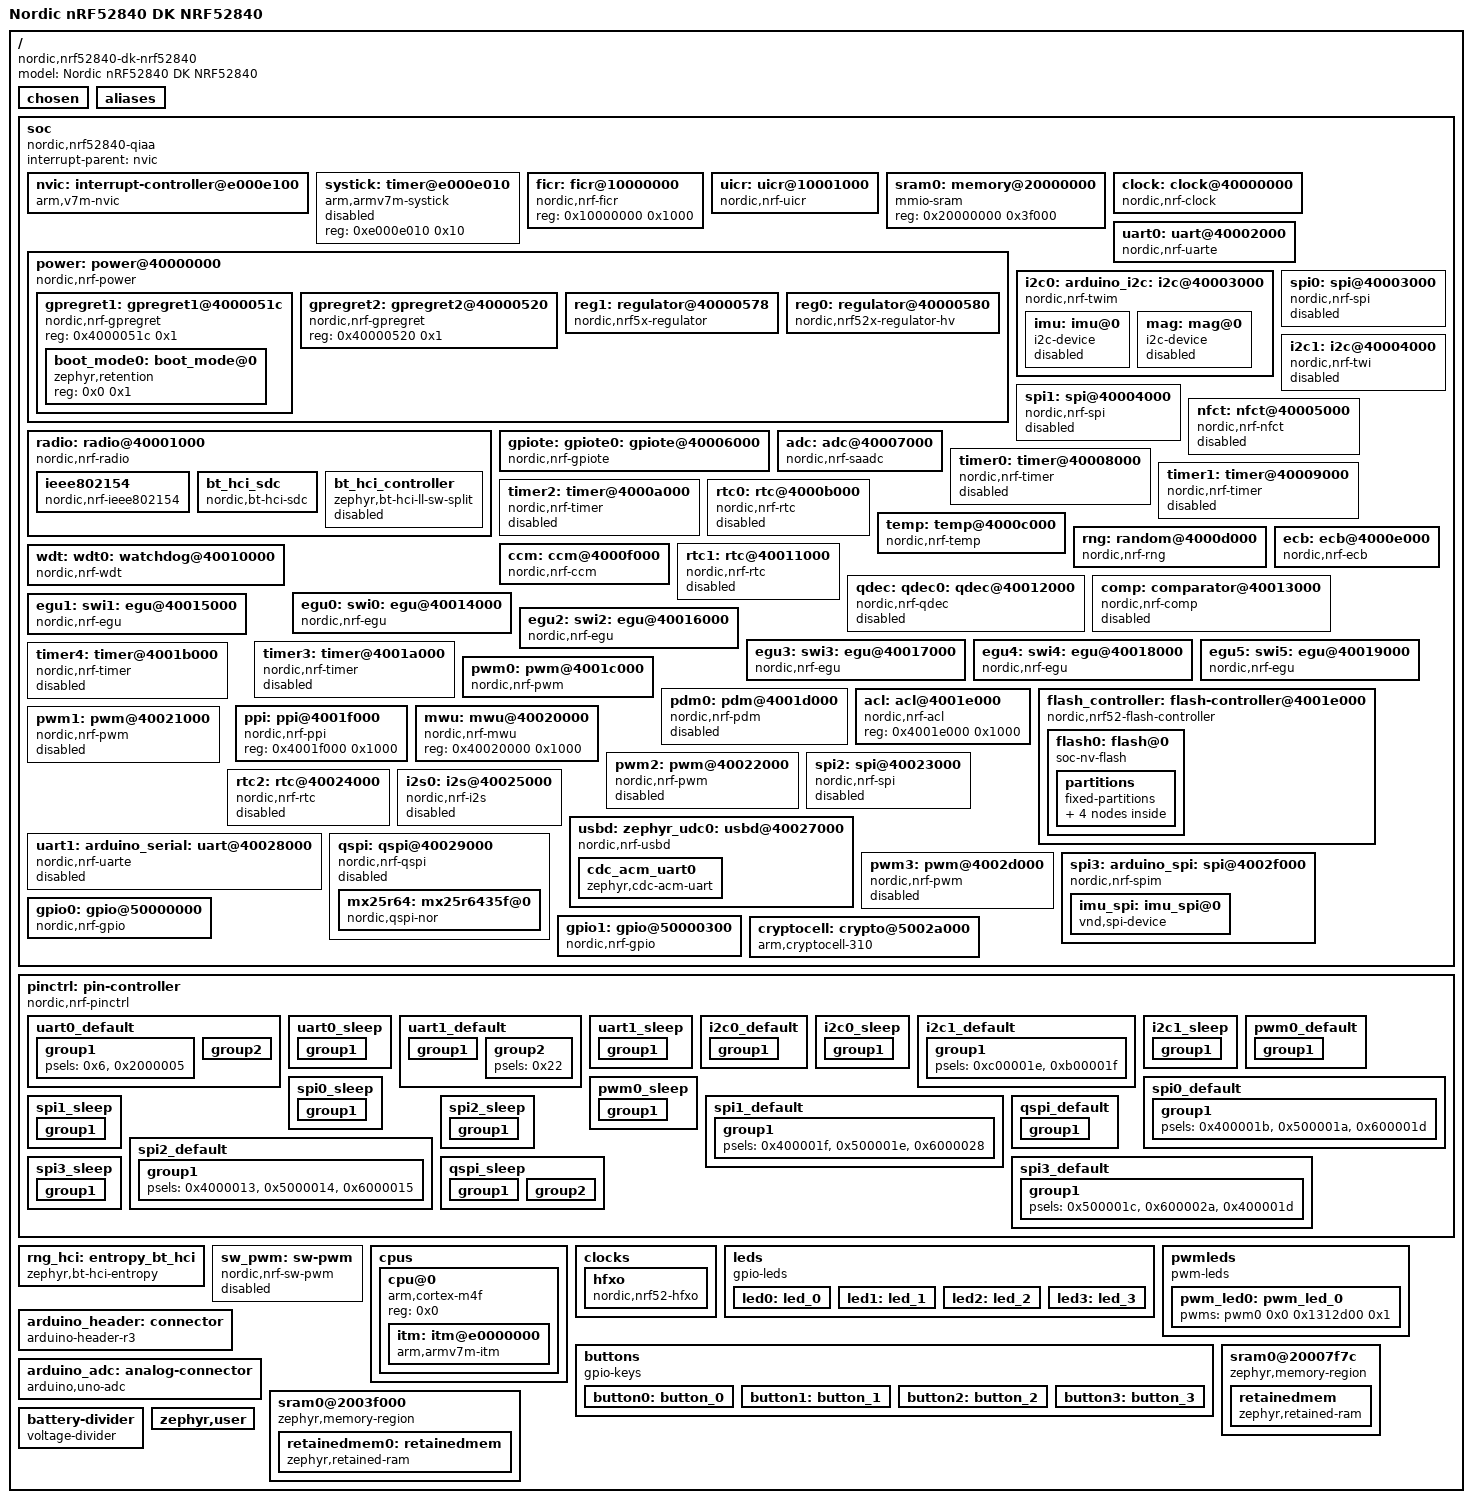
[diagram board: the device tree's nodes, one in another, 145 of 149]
/dts-v1/;

/* node '/' defined in zephyr/dts/common/skeleton.dtsi:9 */
/ {
	#address-cells = < 0x1 >;                   /* in zephyr/dts/common/skeleton.dtsi:10 */
	#size-cells = < 0x1 >;                      /* in zephyr/dts/common/skeleton.dtsi:11 */
	model = "Nordic nRF52840 DK NRF52840";      /* in zephyr/boards/nordic/nrf52840dk/nrf52840dk_nrf52840.dts:14 */
	compatible = "nordic,nrf52840-dk-nrf52840"; /* in zephyr/boards/nordic/nrf52840dk/nrf52840dk_nrf52840.dts:15 */

	/* node '/chosen' defined in zephyr/dts/common/skeleton.dtsi:12 */
	chosen {
		zephyr,bt-hci = &bt_hci_sdc;                 /* in zephyr/dts/arm/nordic/nrf52840.dtsi:10 */
		zephyr,entropy = &cryptocell;                /* in zephyr/dts/arm/nordic/nrf52840.dtsi:11 */
		zephyr,flash-controller = &flash_controller; /* in zephyr/dts/arm/nordic/nrf52840.dtsi:12 */
		zephyr,sram = &sram0;                        /* in zephyr/dts/vendor/nordic/nrf52840_partition.dtsi:9 */
		zephyr,flash = &flash0;                      /* in zephyr/dts/vendor/nordic/nrf52840_partition.dtsi:10 */
		zephyr,code-partition = &slot0_partition;    /* in zephyr/dts/vendor/nordic/nrf52840_partition.dtsi:11 */
		zephyr,console = &cdc_acm_uart0;             /* in app/boards/nrf52840dk_nrf52840.overlay:76 */
		zephyr,shell-uart = &cdc_acm_uart0;          /* in app/boards/nrf52840dk_nrf52840.overlay:77 */
		zephyr,uart-mcumgr = &uart0;                 /* in zephyr/boards/nordic/nrf52840dk/nrf52840dk_nrf52840.dts:20 */
		zephyr,bt-mon-uart = &uart0;                 /* in zephyr/boards/nordic/nrf52840dk/nrf52840dk_nrf52840.dts:21 */
		zephyr,bt-c2h-uart = &uart0;                 /* in zephyr/boards/nordic/nrf52840dk/nrf52840dk_nrf52840.dts:22 */
		zephyr,ieee802154 = &ieee802154;             /* in zephyr/boards/nordic/nrf52840dk/nrf52840dk_nrf52840.dts:23 */
		zephyr,boot-mode = &boot_mode0;              /* in zephyr/boards/nordic/nrf52840dk/nrf52840dk_nrf52840.dts:24 */
	};

	/* node '/aliases' defined in zephyr/dts/common/skeleton.dtsi:13 */
	aliases {
		led0 = &led0;                      /* in zephyr/boards/nordic/nrf52840dk/nrf52840dk_nrf52840.dts:129 */
		led1 = &led1;                      /* in zephyr/boards/nordic/nrf52840dk/nrf52840dk_nrf52840.dts:130 */
		led2 = &led2;                      /* in zephyr/boards/nordic/nrf52840dk/nrf52840dk_nrf52840.dts:131 */
		led3 = &led3;                      /* in zephyr/boards/nordic/nrf52840dk/nrf52840dk_nrf52840.dts:132 */
		pwm-led0 = &pwm_led0;              /* in zephyr/boards/nordic/nrf52840dk/nrf52840dk_nrf52840.dts:133 */
		sw0 = &button0;                    /* in zephyr/boards/nordic/nrf52840dk/nrf52840dk_nrf52840.dts:134 */
		sw1 = &button1;                    /* in zephyr/boards/nordic/nrf52840dk/nrf52840dk_nrf52840.dts:135 */
		sw2 = &button2;                    /* in zephyr/boards/nordic/nrf52840dk/nrf52840dk_nrf52840.dts:136 */
		sw3 = &button3;                    /* in zephyr/boards/nordic/nrf52840dk/nrf52840dk_nrf52840.dts:137 */
		bootloader-led0 = &led0;           /* in zephyr/boards/nordic/nrf52840dk/nrf52840dk_nrf52840.dts:138 */
		mcuboot-button0 = &button0;        /* in zephyr/boards/nordic/nrf52840dk/nrf52840dk_nrf52840.dts:139 */
		mcuboot-led0 = &led0;              /* in zephyr/boards/nordic/nrf52840dk/nrf52840dk_nrf52840.dts:140 */
		watchdog0 = &wdt0;                 /* in zephyr/boards/nordic/nrf52840dk/nrf52840dk_nrf52840.dts:141 */
		retainedmemdevice = &retainedmem0; /* in app/socs/nrf52840.overlay:27 */
	};

	/* node '/soc' defined in zephyr/dts/arm/armv7-m.dtsi:6 */
	soc {
		#address-cells = < 0x1 >;            /* in zephyr/dts/arm/armv7-m.dtsi:7 */
		#size-cells = < 0x1 >;               /* in zephyr/dts/arm/armv7-m.dtsi:8 */
		compatible = "nordic,nrf52840-qiaa",
		             "nordic,nrf52840",
		             "nordic,nrf52",
		             "simple-bus";           /* in zephyr/dts/arm/nordic/nrf52840_qiaa.dtsi:29 */
		interrupt-parent = < &nvic >;        /* in zephyr/dts/arm/armv7-m.dtsi:10 */
		ranges;                              /* in zephyr/dts/arm/armv7-m.dtsi:11 */

		/* node '/soc/interrupt-controller@e000e100' defined in zephyr/dts/arm/armv7-m.dtsi:13 */
		nvic: interrupt-controller@e000e100 {
			#address-cells = < 0x1 >;            /* in zephyr/dts/arm/armv7-m.dtsi:14 */
			compatible = "arm,v7m-nvic";         /* in zephyr/dts/arm/armv7-m.dtsi:15 */
			reg = < 0xe000e100 0xc00 >;          /* in zephyr/dts/arm/armv7-m.dtsi:16 */
			interrupt-controller;                /* in zephyr/dts/arm/armv7-m.dtsi:17 */
			#interrupt-cells = < 0x2 >;          /* in zephyr/dts/arm/armv7-m.dtsi:18 */
			arm,num-irq-priority-bits = < 0x3 >; /* in zephyr/dts/arm/nordic/nrf52840.dtsi:582 */
			phandle = < 0x1 >;                   /* in zephyr/dts/arm/armv7-m.dtsi:10 */
		};

		/* node '/soc/timer@e000e010' defined in zephyr/dts/arm/armv7-m.dtsi:21 */
		systick: timer@e000e010 {
			compatible = "arm,armv7m-systick"; /* in zephyr/dts/arm/armv7-m.dtsi:22 */
			reg = < 0xe000e010 0x10 >;         /* in zephyr/dts/arm/armv7-m.dtsi:23 */
			status = "disabled";               /* in zephyr/dts/arm/nordic/nrf52840.dtsi:587 */
		};

		/* node '/soc/ficr@10000000' defined in zephyr/dts/arm/nordic/nrf52840.dtsi:44 */
		ficr: ficr@10000000 {
			compatible = "nordic,nrf-ficr"; /* in zephyr/dts/arm/nordic/nrf52840.dtsi:45 */
			reg = < 0x10000000 0x1000 >;    /* in zephyr/dts/arm/nordic/nrf52840.dtsi:46 */
			#nordic,ficr-cells = < 0x1 >;   /* in zephyr/dts/arm/nordic/nrf52840.dtsi:47 */
			status = "okay";                /* in zephyr/dts/arm/nordic/nrf52840.dtsi:48 */
		};

		/* node '/soc/uicr@10001000' defined in zephyr/dts/arm/nordic/nrf52840.dtsi:51 */
		uicr: uicr@10001000 {
			compatible = "nordic,nrf-uicr"; /* in zephyr/dts/arm/nordic/nrf52840.dtsi:52 */
			reg = < 0x10001000 0x1000 >;    /* in zephyr/dts/arm/nordic/nrf52840.dtsi:53 */
			status = "okay";                /* in zephyr/dts/arm/nordic/nrf52840.dtsi:54 */
			gpio-as-nreset;                 /* in zephyr/boards/nordic/nrf52840dk/nrf52840dk_nrf52840.dts:158 */
		};

		/* node '/soc/memory@20000000' defined in zephyr/dts/arm/nordic/nrf52840.dtsi:57 */
		sram0: memory@20000000 {
			compatible = "mmio-sram";     /* in zephyr/dts/arm/nordic/nrf52840.dtsi:58 */
			reg = < 0x20000000 0x3f000 >; /* in app/socs/nrf52840.overlay:33 */
		};

		/* node '/soc/clock@40000000' defined in zephyr/dts/arm/nordic/nrf52840.dtsi:61 */
		clock: clock@40000000 {
			compatible = "nordic,nrf-clock"; /* in zephyr/dts/arm/nordic/nrf52840.dtsi:62 */
			reg = < 0x40000000 0x1000 >;     /* in zephyr/dts/arm/nordic/nrf52840.dtsi:63 */
			interrupts = < 0x0 0x1 >;        /* in zephyr/dts/arm/nordic/nrf52840.dtsi:64 */
			status = "okay";                 /* in zephyr/dts/arm/nordic/nrf52840.dtsi:65 */
		};

		/* node '/soc/power@40000000' defined in zephyr/dts/arm/nordic/nrf52840.dtsi:68 */
		power: power@40000000 {
			compatible = "nordic,nrf-power"; /* in zephyr/dts/arm/nordic/nrf52840.dtsi:69 */
			reg = < 0x40000000 0x1000 >;     /* in zephyr/dts/arm/nordic/nrf52840.dtsi:70 */
			interrupts = < 0x0 0x1 >;        /* in zephyr/dts/arm/nordic/nrf52840.dtsi:71 */
			status = "okay";                 /* in zephyr/dts/arm/nordic/nrf52840.dtsi:72 */
			#address-cells = < 0x1 >;        /* in zephyr/dts/arm/nordic/nrf52840.dtsi:73 */
			#size-cells = < 0x1 >;           /* in zephyr/dts/arm/nordic/nrf52840.dtsi:74 */

			/* node '/soc/power@40000000/gpregret1@4000051c' defined in zephyr/dts/arm/nordic/nrf52840.dtsi:76 */
			gpregret1: gpregret1@4000051c {
				#address-cells = < 0x1 >;           /* in zephyr/dts/arm/nordic/nrf52840.dtsi:77 */
				#size-cells = < 0x1 >;              /* in zephyr/dts/arm/nordic/nrf52840.dtsi:78 */
				compatible = "nordic,nrf-gpregret"; /* in zephyr/dts/arm/nordic/nrf52840.dtsi:79 */
				reg = < 0x4000051c 0x1 >;           /* in zephyr/dts/arm/nordic/nrf52840.dtsi:80 */
				status = "okay";                    /* in zephyr/boards/nordic/nrf52840dk/nrf52840dk_nrf52840.dts:296 */

				/* node '/soc/power@40000000/gpregret1@4000051c/boot_mode@0' defined in zephyr/boards/nordic/nrf52840dk/nrf52840dk_nrf52840.dts:298 */
				boot_mode0: boot_mode@0 {
					compatible = "zephyr,retention"; /* in zephyr/boards/nordic/nrf52840dk/nrf52840dk_nrf52840.dts:299 */
					status = "okay";                 /* in zephyr/boards/nordic/nrf52840dk/nrf52840dk_nrf52840.dts:300 */
					reg = < 0x0 0x1 >;               /* in zephyr/boards/nordic/nrf52840dk/nrf52840dk_nrf52840.dts:301 */
				};
			};

			/* node '/soc/power@40000000/gpregret2@40000520' defined in zephyr/dts/arm/nordic/nrf52840.dtsi:84 */
			gpregret2: gpregret2@40000520 {
				#address-cells = < 0x1 >;           /* in zephyr/dts/arm/nordic/nrf52840.dtsi:85 */
				#size-cells = < 0x1 >;              /* in zephyr/dts/arm/nordic/nrf52840.dtsi:86 */
				compatible = "nordic,nrf-gpregret"; /* in zephyr/dts/arm/nordic/nrf52840.dtsi:87 */
				reg = < 0x40000520 0x1 >;           /* in zephyr/dts/arm/nordic/nrf52840.dtsi:88 */
				status = "okay";                    /* in zephyr/dts/arm/nordic/nrf52840.dtsi:89 */
			};

			/* node '/soc/power@40000000/regulator@40000578' defined in zephyr/dts/arm/nordic/nrf52840.dtsi:92 */
			reg1: regulator@40000578 {
				compatible = "nordic,nrf5x-regulator"; /* in zephyr/dts/arm/nordic/nrf52840.dtsi:93 */
				reg = < 0x40000578 0x1 >;              /* in zephyr/dts/arm/nordic/nrf52840.dtsi:94 */
				regulator-name = "REG1";               /* in zephyr/dts/arm/nordic/nrf52840.dtsi:95 */
				regulator-initial-mode = < 0x1 >;      /* in zephyr/boards/nordic/nrf52840dk/nrf52840dk_nrf52840.dts:150 */
			};

			/* node '/soc/power@40000000/regulator@40000580' defined in zephyr/dts/arm/nordic/nrf52840_qiaa.dtsi:19 */
			reg0: regulator@40000580 {
				compatible = "nordic,nrf52x-regulator-hv"; /* in zephyr/dts/arm/nordic/nrf52840_qiaa.dtsi:20 */
				reg = < 0x40000580 0x1 >;                  /* in zephyr/dts/arm/nordic/nrf52840_qiaa.dtsi:21 */
				regulator-name = "REG0";                   /* in zephyr/dts/arm/nordic/nrf52840_qiaa.dtsi:22 */
				status = "okay";                           /* in zephyr/boards/nordic/nrf52840dk/nrf52840dk_nrf52840.dts:146 */
			};
		};

		/* node '/soc/radio@40001000' defined in zephyr/dts/arm/nordic/nrf52840.dtsi:100 */
		radio: radio@40001000 {
			compatible = "nordic,nrf-radio"; /* in zephyr/dts/arm/nordic/nrf52840.dtsi:101 */
			reg = < 0x40001000 0x1000 >;     /* in zephyr/dts/arm/nordic/nrf52840.dtsi:102 */
			interrupts = < 0x1 0x1 >;        /* in zephyr/dts/arm/nordic/nrf52840.dtsi:103 */
			status = "okay";                 /* in zephyr/dts/arm/nordic/nrf52840.dtsi:104 */
			ieee802154-supported;            /* in zephyr/dts/arm/nordic/nrf52840.dtsi:105 */
			ble-2mbps-supported;             /* in zephyr/dts/arm/nordic/nrf52840.dtsi:106 */
			ble-coded-phy-supported;         /* in zephyr/dts/arm/nordic/nrf52840.dtsi:107 */
			tx-high-power-supported;         /* in zephyr/dts/arm/nordic/nrf52840.dtsi:108 */

			/* node '/soc/radio@40001000/ieee802154' defined in zephyr/dts/arm/nordic/nrf52840.dtsi:110 */
			ieee802154: ieee802154 {
				compatible = "nordic,nrf-ieee802154"; /* in zephyr/dts/arm/nordic/nrf52840.dtsi:111 */
				status = "okay";                      /* in zephyr/boards/nordic/nrf52840dk/nrf52840dk_nrf52840.dts:287 */
			};

			/* node '/soc/radio@40001000/bt_hci_sdc' defined in zephyr/dts/arm/nordic/nrf52840.dtsi:115 */
			bt_hci_sdc: bt_hci_sdc {
				compatible = "nordic,bt-hci-sdc"; /* in zephyr/dts/arm/nordic/nrf52840.dtsi:116 */
				status = "okay";                  /* in zephyr/dts/arm/nordic/nrf52840.dtsi:117 */
			};

			/* node '/soc/radio@40001000/bt_hci_controller' defined in zephyr/dts/arm/nordic/nrf52840.dtsi:119 */
			bt_hci_controller: bt_hci_controller {
				compatible = "zephyr,bt-hci-ll-sw-split"; /* in zephyr/dts/arm/nordic/nrf52840.dtsi:120 */
				status = "disabled";                      /* in zephyr/dts/arm/nordic/nrf52840.dtsi:121 */
			};
		};

		/* node '/soc/uart@40002000' defined in zephyr/dts/arm/nordic/nrf52840.dtsi:125 */
		uart0: uart@40002000 {
			compatible = "nordic,nrf-uarte"; /* in zephyr/boards/nordic/nrf52840dk/nrf52840dk_nrf52840.dts:186 */
			reg = < 0x40002000 0x1000 >;     /* in zephyr/dts/arm/nordic/nrf52840.dtsi:129 */
			interrupts = < 0x2 0x1 >;        /* in zephyr/dts/arm/nordic/nrf52840.dtsi:130 */
			status = "okay";                 /* in zephyr/boards/nordic/nrf52840dk/nrf52840dk_nrf52840.dts:187 */
			current-speed = < 0x1c200 >;     /* in zephyr/boards/nordic/nrf52840dk/nrf52840dk_nrf52840.dts:188 */
			pinctrl-0 = < &uart0_default >;  /* in zephyr/boards/nordic/nrf52840dk/nrf52840dk_nrf52840.dts:189 */
			pinctrl-1 = < &uart0_sleep >;    /* in zephyr/boards/nordic/nrf52840dk/nrf52840dk_nrf52840.dts:190 */
			pinctrl-names = "default",
			                "sleep";         /* in zephyr/boards/nordic/nrf52840dk/nrf52840dk_nrf52840.dts:191 */
		};

		/* node '/soc/i2c@40003000' defined in zephyr/dts/arm/nordic/nrf52840.dtsi:134 */
		i2c0: arduino_i2c: i2c@40003000 {
			compatible = "nordic,nrf-twim";        /* in app/boards/nrf52840dk_nrf52840.overlay:110 */
			#address-cells = < 0x1 >;              /* in zephyr/dts/arm/nordic/nrf52840.dtsi:143 */
			#size-cells = < 0x0 >;                 /* in zephyr/dts/arm/nordic/nrf52840.dtsi:144 */
			reg = < 0x40003000 0x1000 >;           /* in zephyr/dts/arm/nordic/nrf52840.dtsi:145 */
			interrupts = < 0x3 0x1 >;              /* in zephyr/dts/arm/nordic/nrf52840.dtsi:146 */
			easydma-maxcnt-bits = < 0x10 >;        /* in zephyr/dts/arm/nordic/nrf52840.dtsi:147 */
			status = "okay";                       /* in zephyr/boards/nordic/nrf52840dk/nrf52840dk_nrf52840.dts:203 */
			zephyr,pm-device-runtime-auto;         /* in zephyr/dts/arm/nordic/nrf52840.dtsi:149 */
			pinctrl-0 = < &i2c0_default >;         /* in zephyr/boards/nordic/nrf52840dk/nrf52840dk_nrf52840.dts:204 */
			pinctrl-1 = < &i2c0_sleep >;           /* in zephyr/boards/nordic/nrf52840dk/nrf52840dk_nrf52840.dts:205 */
			pinctrl-names = "default",
			                "sleep";               /* in zephyr/boards/nordic/nrf52840dk/nrf52840dk_nrf52840.dts:206 */
			zephyr,concat-buf-size = < 0x3ff >;    /* in app/boards/nrf52840dk_nrf52840.overlay:111 */
			zephyr,flash-buf-max-size = < 0x3ff >; /* in app/boards/nrf52840dk_nrf52840.overlay:112 */
			clock-frequency = < 0x61a80 >;         /* in app/boards/nrf52840dk_nrf52840.overlay:113 */

			/* node '/soc/i2c@40003000/imu@0' defined in app/boards/nrf52840dk_nrf52840.overlay:115 */
			imu: imu@0 {
				compatible = "i2c-device"; /* in app/boards/nrf52840dk_nrf52840.overlay:116 */
				label = "imu";             /* in app/boards/nrf52840dk_nrf52840.overlay:117 */
				reg = < 0x0 >;             /* in app/boards/nrf52840dk_nrf52840.overlay:118 */
				status = "disabled";       /* in app/boards/nrf52840dk_nrf52840.overlay:120 */
			};

			/* node '/soc/i2c@40003000/mag@0' defined in app/boards/nrf52840dk_nrf52840.overlay:123 */
			mag: mag@0 {
				compatible = "i2c-device"; /* in app/boards/nrf52840dk_nrf52840.overlay:124 */
				label = "mag";             /* in app/boards/nrf52840dk_nrf52840.overlay:125 */
				reg = < 0x0 >;             /* in app/boards/nrf52840dk_nrf52840.overlay:126 */
				status = "disabled";       /* in app/boards/nrf52840dk_nrf52840.overlay:136 */
			};
		};

		/* node '/soc/spi@40003000' defined in zephyr/dts/arm/nordic/nrf52840.dtsi:152 */
		spi0: spi@40003000 {
			compatible = "nordic,nrf-spi";  /* in zephyr/boards/nordic/nrf52840dk/nrf52840dk_nrf52840.dts:226 */
			#address-cells = < 0x1 >;       /* in zephyr/dts/arm/nordic/nrf52840.dtsi:161 */
			#size-cells = < 0x0 >;          /* in zephyr/dts/arm/nordic/nrf52840.dtsi:162 */
			reg = < 0x40003000 0x1000 >;    /* in zephyr/dts/arm/nordic/nrf52840.dtsi:163 */
			interrupts = < 0x3 0x1 >;       /* in zephyr/dts/arm/nordic/nrf52840.dtsi:164 */
			max-frequency = < 0x7a1200 >;   /* in zephyr/dts/arm/nordic/nrf52840.dtsi:165 */
			easydma-maxcnt-bits = < 0x10 >; /* in zephyr/dts/arm/nordic/nrf52840.dtsi:166 */
			status = "disabled";            /* in zephyr/dts/arm/nordic/nrf52840.dtsi:167 */
			pinctrl-0 = < &spi0_default >;  /* in zephyr/boards/nordic/nrf52840dk/nrf52840dk_nrf52840.dts:229 */
			pinctrl-1 = < &spi0_sleep >;    /* in zephyr/boards/nordic/nrf52840dk/nrf52840dk_nrf52840.dts:230 */
			pinctrl-names = "default",
			                "sleep";        /* in zephyr/boards/nordic/nrf52840dk/nrf52840dk_nrf52840.dts:231 */
		};

		/* node '/soc/i2c@40004000' defined in zephyr/dts/arm/nordic/nrf52840.dtsi:170 */
		i2c1: i2c@40004000 {
			compatible = "nordic,nrf-twi";  /* in zephyr/boards/nordic/nrf52840dk/nrf52840dk_nrf52840.dts:210 */
			#address-cells = < 0x1 >;       /* in zephyr/dts/arm/nordic/nrf52840.dtsi:179 */
			#size-cells = < 0x0 >;          /* in zephyr/dts/arm/nordic/nrf52840.dtsi:180 */
			reg = < 0x40004000 0x1000 >;    /* in zephyr/dts/arm/nordic/nrf52840.dtsi:181 */
			interrupts = < 0x4 0x1 >;       /* in zephyr/dts/arm/nordic/nrf52840.dtsi:182 */
			easydma-maxcnt-bits = < 0x10 >; /* in zephyr/dts/arm/nordic/nrf52840.dtsi:183 */
			status = "disabled";            /* in zephyr/dts/arm/nordic/nrf52840.dtsi:184 */
			zephyr,pm-device-runtime-auto;  /* in zephyr/dts/arm/nordic/nrf52840.dtsi:185 */
			pinctrl-0 = < &i2c1_default >;  /* in zephyr/boards/nordic/nrf52840dk/nrf52840dk_nrf52840.dts:213 */
			pinctrl-1 = < &i2c1_sleep >;    /* in zephyr/boards/nordic/nrf52840dk/nrf52840dk_nrf52840.dts:214 */
			pinctrl-names = "default",
			                "sleep";        /* in zephyr/boards/nordic/nrf52840dk/nrf52840dk_nrf52840.dts:215 */
		};

		/* node '/soc/spi@40004000' defined in zephyr/dts/arm/nordic/nrf52840.dtsi:188 */
		spi1: spi@40004000 {
			compatible = "nordic,nrf-spi";  /* in zephyr/boards/nordic/nrf52840dk/nrf52840dk_nrf52840.dts:235 */
			#address-cells = < 0x1 >;       /* in zephyr/dts/arm/nordic/nrf52840.dtsi:197 */
			#size-cells = < 0x0 >;          /* in zephyr/dts/arm/nordic/nrf52840.dtsi:198 */
			reg = < 0x40004000 0x1000 >;    /* in zephyr/dts/arm/nordic/nrf52840.dtsi:199 */
			interrupts = < 0x4 0x1 >;       /* in zephyr/dts/arm/nordic/nrf52840.dtsi:200 */
			max-frequency = < 0x7a1200 >;   /* in zephyr/dts/arm/nordic/nrf52840.dtsi:201 */
			easydma-maxcnt-bits = < 0x10 >; /* in zephyr/dts/arm/nordic/nrf52840.dtsi:202 */
			status = "disabled";            /* in app/boards/nrf52840dk_nrf52840.overlay:63 */
			pinctrl-0 = < &spi1_default >;  /* in zephyr/boards/nordic/nrf52840dk/nrf52840dk_nrf52840.dts:237 */
			pinctrl-1 = < &spi1_sleep >;    /* in zephyr/boards/nordic/nrf52840dk/nrf52840dk_nrf52840.dts:238 */
			pinctrl-names = "default",
			                "sleep";        /* in zephyr/boards/nordic/nrf52840dk/nrf52840dk_nrf52840.dts:239 */
		};

		/* node '/soc/nfct@40005000' defined in zephyr/dts/arm/nordic/nrf52840.dtsi:206 */
		nfct: nfct@40005000 {
			compatible = "nordic,nrf-nfct"; /* in zephyr/dts/arm/nordic/nrf52840.dtsi:207 */
			reg = < 0x40005000 0x1000 >;    /* in zephyr/dts/arm/nordic/nrf52840.dtsi:208 */
			interrupts = < 0x5 0x1 >;       /* in zephyr/dts/arm/nordic/nrf52840.dtsi:209 */
			status = "disabled";            /* in app/boards/nrf52840dk_nrf52840.overlay:71 */
		};

		/* node '/soc/gpiote@40006000' defined in zephyr/dts/arm/nordic/nrf52840.dtsi:213 */
		gpiote: gpiote0: gpiote@40006000 {
			compatible = "nordic,nrf-gpiote"; /* in zephyr/dts/arm/nordic/nrf52840.dtsi:214 */
			reg = < 0x40006000 0x1000 >;      /* in zephyr/dts/arm/nordic/nrf52840.dtsi:215 */
			interrupts = < 0x6 0x5 >;         /* in zephyr/dts/arm/nordic/nrf52840.dtsi:216 */
			status = "okay";                  /* in zephyr/boards/nordic/nrf52840dk/nrf52840dk_nrf52840.dts:162 */
			instance = < 0x0 >;               /* in zephyr/dts/arm/nordic/nrf52840.dtsi:218 */
			phandle = < 0x17 >;               /* in zephyr/dts/arm/nordic/nrf52840.dtsi:556 */
		};

		/* node '/soc/adc@40007000' defined in zephyr/dts/arm/nordic/nrf52840.dtsi:221 */
		adc: adc@40007000 {
			compatible = "nordic,nrf-saadc"; /* in zephyr/dts/arm/nordic/nrf52840.dtsi:222 */
			reg = < 0x40007000 0x1000 >;     /* in zephyr/dts/arm/nordic/nrf52840.dtsi:223 */
			interrupts = < 0x7 0x1 >;        /* in zephyr/dts/arm/nordic/nrf52840.dtsi:224 */
			status = "okay";                 /* in app/boards/nrf52840dk_nrf52840.overlay:106 */
			#io-channel-cells = < 0x1 >;     /* in zephyr/dts/arm/nordic/nrf52840.dtsi:226 */
			zephyr,pm-device-runtime-auto;   /* in zephyr/dts/arm/nordic/nrf52840.dtsi:227 */
			phandle = < 0x1b >;              /* in zephyr/boards/nordic/nrf52840dk/nrf52840dk_nrf52840.dts:119 */
		};

		/* node '/soc/timer@40008000' defined in zephyr/dts/arm/nordic/nrf52840.dtsi:230 */
		timer0: timer@40008000 {
			compatible = "nordic,nrf-timer"; /* in zephyr/dts/arm/nordic/nrf52840.dtsi:231 */
			status = "disabled";             /* in zephyr/dts/arm/nordic/nrf52840.dtsi:232 */
			reg = < 0x40008000 0x1000 >;     /* in zephyr/dts/arm/nordic/nrf52840.dtsi:233 */
			cc-num = < 0x4 >;                /* in zephyr/dts/arm/nordic/nrf52840.dtsi:234 */
			max-bit-width = < 0x20 >;        /* in zephyr/dts/arm/nordic/nrf52840.dtsi:235 */
			interrupts = < 0x8 0x1 >;        /* in zephyr/dts/arm/nordic/nrf52840.dtsi:236 */
			prescaler = < 0x0 >;             /* in zephyr/dts/arm/nordic/nrf52840.dtsi:237 */
		};

		/* node '/soc/timer@40009000' defined in zephyr/dts/arm/nordic/nrf52840.dtsi:240 */
		timer1: timer@40009000 {
			compatible = "nordic,nrf-timer"; /* in zephyr/dts/arm/nordic/nrf52840.dtsi:241 */
			status = "disabled";             /* in zephyr/dts/arm/nordic/nrf52840.dtsi:242 */
			reg = < 0x40009000 0x1000 >;     /* in zephyr/dts/arm/nordic/nrf52840.dtsi:243 */
			cc-num = < 0x4 >;                /* in zephyr/dts/arm/nordic/nrf52840.dtsi:244 */
			max-bit-width = < 0x20 >;        /* in zephyr/dts/arm/nordic/nrf52840.dtsi:245 */
			interrupts = < 0x9 0x1 >;        /* in zephyr/dts/arm/nordic/nrf52840.dtsi:246 */
			prescaler = < 0x0 >;             /* in zephyr/dts/arm/nordic/nrf52840.dtsi:247 */
			phandle = < 0x18 >;              /* in zephyr/dts/vendor/nordic/nrf_common.dtsi:41 */
		};

		/* node '/soc/timer@4000a000' defined in zephyr/dts/arm/nordic/nrf52840.dtsi:250 */
		timer2: timer@4000a000 {
			compatible = "nordic,nrf-timer"; /* in zephyr/dts/arm/nordic/nrf52840.dtsi:251 */
			status = "disabled";             /* in zephyr/dts/arm/nordic/nrf52840.dtsi:252 */
			reg = < 0x4000a000 0x1000 >;     /* in zephyr/dts/arm/nordic/nrf52840.dtsi:253 */
			cc-num = < 0x4 >;                /* in zephyr/dts/arm/nordic/nrf52840.dtsi:254 */
			max-bit-width = < 0x20 >;        /* in zephyr/dts/arm/nordic/nrf52840.dtsi:255 */
			interrupts = < 0xa 0x1 >;        /* in zephyr/dts/arm/nordic/nrf52840.dtsi:256 */
			prescaler = < 0x0 >;             /* in zephyr/dts/arm/nordic/nrf52840.dtsi:257 */
		};

		/* node '/soc/rtc@4000b000' defined in zephyr/dts/arm/nordic/nrf52840.dtsi:260 */
		rtc0: rtc@4000b000 {
			compatible = "nordic,nrf-rtc"; /* in zephyr/dts/arm/nordic/nrf52840.dtsi:261 */
			reg = < 0x4000b000 0x1000 >;   /* in zephyr/dts/arm/nordic/nrf52840.dtsi:262 */
			cc-num = < 0x3 >;              /* in zephyr/dts/arm/nordic/nrf52840.dtsi:263 */
			interrupts = < 0xb 0x1 >;      /* in zephyr/dts/arm/nordic/nrf52840.dtsi:264 */
			status = "disabled";           /* in zephyr/dts/arm/nordic/nrf52840.dtsi:265 */
			clock-frequency = < 0x8000 >;  /* in zephyr/dts/arm/nordic/nrf52840.dtsi:266 */
			prescaler = < 0x1 >;           /* in zephyr/dts/arm/nordic/nrf52840.dtsi:267 */
		};

		/* node '/soc/temp@4000c000' defined in zephyr/dts/arm/nordic/nrf52840.dtsi:270 */
		temp: temp@4000c000 {
			compatible = "nordic,nrf-temp"; /* in zephyr/dts/arm/nordic/nrf52840.dtsi:271 */
			reg = < 0x4000c000 0x1000 >;    /* in zephyr/dts/arm/nordic/nrf52840.dtsi:272 */
			interrupts = < 0xc 0x1 >;       /* in zephyr/dts/arm/nordic/nrf52840.dtsi:273 */
			status = "okay";                /* in zephyr/dts/arm/nordic/nrf52840.dtsi:274 */
		};

		/* node '/soc/random@4000d000' defined in zephyr/dts/arm/nordic/nrf52840.dtsi:277 */
		rng: random@4000d000 {
			compatible = "nordic,nrf-rng"; /* in zephyr/dts/arm/nordic/nrf52840.dtsi:278 */
			reg = < 0x4000d000 0x1000 >;   /* in zephyr/dts/arm/nordic/nrf52840.dtsi:279 */
			interrupts = < 0xd 0x1 >;      /* in zephyr/dts/arm/nordic/nrf52840.dtsi:280 */
			status = "okay";               /* in zephyr/dts/arm/nordic/nrf52840.dtsi:281 */
		};

		/* node '/soc/ecb@4000e000' defined in zephyr/dts/arm/nordic/nrf52840.dtsi:284 */
		ecb: ecb@4000e000 {
			compatible = "nordic,nrf-ecb"; /* in zephyr/dts/arm/nordic/nrf52840.dtsi:285 */
			reg = < 0x4000e000 0x1000 >;   /* in zephyr/dts/arm/nordic/nrf52840.dtsi:286 */
			interrupts = < 0xe 0x1 >;      /* in zephyr/dts/arm/nordic/nrf52840.dtsi:287 */
			status = "okay";               /* in zephyr/dts/arm/nordic/nrf52840.dtsi:288 */
		};

		/* node '/soc/ccm@4000f000' defined in zephyr/dts/arm/nordic/nrf52840.dtsi:291 */
		ccm: ccm@4000f000 {
			compatible = "nordic,nrf-ccm"; /* in zephyr/dts/arm/nordic/nrf52840.dtsi:292 */
			reg = < 0x4000f000 0x1000 >;   /* in zephyr/dts/arm/nordic/nrf52840.dtsi:293 */
			interrupts = < 0xf 0x1 >;      /* in zephyr/dts/arm/nordic/nrf52840.dtsi:294 */
			length-field-length-8-bits;    /* in zephyr/dts/arm/nordic/nrf52840.dtsi:295 */
			status = "okay";               /* in zephyr/dts/arm/nordic/nrf52840.dtsi:296 */
		};

		/* node '/soc/watchdog@40010000' defined in zephyr/dts/arm/nordic/nrf52840.dtsi:299 */
		wdt: wdt0: watchdog@40010000 {
			compatible = "nordic,nrf-wdt"; /* in zephyr/dts/arm/nordic/nrf52840.dtsi:300 */
			reg = < 0x40010000 0x1000 >;   /* in zephyr/dts/arm/nordic/nrf52840.dtsi:301 */
			interrupts = < 0x10 0x1 >;     /* in zephyr/dts/arm/nordic/nrf52840.dtsi:302 */
			status = "okay";               /* in zephyr/dts/arm/nordic/nrf52840.dtsi:303 */
		};

		/* node '/soc/rtc@40011000' defined in zephyr/dts/arm/nordic/nrf52840.dtsi:306 */
		rtc1: rtc@40011000 {
			compatible = "nordic,nrf-rtc"; /* in zephyr/dts/arm/nordic/nrf52840.dtsi:307 */
			reg = < 0x40011000 0x1000 >;   /* in zephyr/dts/arm/nordic/nrf52840.dtsi:308 */
			cc-num = < 0x4 >;              /* in zephyr/dts/arm/nordic/nrf52840.dtsi:309 */
			interrupts = < 0x11 0x1 >;     /* in zephyr/dts/arm/nordic/nrf52840.dtsi:310 */
			status = "disabled";           /* in zephyr/dts/arm/nordic/nrf52840.dtsi:311 */
			clock-frequency = < 0x8000 >;  /* in zephyr/dts/arm/nordic/nrf52840.dtsi:312 */
			prescaler = < 0x1 >;           /* in zephyr/dts/arm/nordic/nrf52840.dtsi:313 */
		};

		/* node '/soc/qdec@40012000' defined in zephyr/dts/arm/nordic/nrf52840.dtsi:316 */
		qdec: qdec0: qdec@40012000 {
			compatible = "nordic,nrf-qdec"; /* in zephyr/dts/arm/nordic/nrf52840.dtsi:317 */
			reg = < 0x40012000 0x1000 >;    /* in zephyr/dts/arm/nordic/nrf52840.dtsi:318 */
			interrupts = < 0x12 0x1 >;      /* in zephyr/dts/arm/nordic/nrf52840.dtsi:319 */
			status = "disabled";            /* in zephyr/dts/arm/nordic/nrf52840.dtsi:320 */
		};

		/* node '/soc/comparator@40013000' defined in zephyr/dts/arm/nordic/nrf52840.dtsi:323 */
		comp: comparator@40013000 {
			compatible = "nordic,nrf-comp"; /* in zephyr/dts/arm/nordic/nrf52840.dtsi:328 */
			reg = < 0x40013000 0x1000 >;    /* in zephyr/dts/arm/nordic/nrf52840.dtsi:329 */
			interrupts = < 0x13 0x1 >;      /* in zephyr/dts/arm/nordic/nrf52840.dtsi:330 */
			status = "disabled";            /* in zephyr/dts/arm/nordic/nrf52840.dtsi:331 */
		};

		/* node '/soc/egu@40014000' defined in zephyr/dts/arm/nordic/nrf52840.dtsi:334 */
		egu0: swi0: egu@40014000 {
			compatible = "nordic,nrf-egu",
			             "nordic,nrf-swi"; /* in zephyr/dts/arm/nordic/nrf52840.dtsi:335 */
			reg = < 0x40014000 0x1000 >;   /* in zephyr/dts/arm/nordic/nrf52840.dtsi:336 */
			interrupts = < 0x14 0x1 >;     /* in zephyr/dts/arm/nordic/nrf52840.dtsi:337 */
			status = "okay";               /* in zephyr/dts/arm/nordic/nrf52840.dtsi:338 */
		};

		/* node '/soc/egu@40015000' defined in zephyr/dts/arm/nordic/nrf52840.dtsi:341 */
		egu1: swi1: egu@40015000 {
			compatible = "nordic,nrf-egu",
			             "nordic,nrf-swi"; /* in zephyr/dts/arm/nordic/nrf52840.dtsi:342 */
			reg = < 0x40015000 0x1000 >;   /* in zephyr/dts/arm/nordic/nrf52840.dtsi:343 */
			interrupts = < 0x15 0x1 >;     /* in zephyr/dts/arm/nordic/nrf52840.dtsi:344 */
			status = "okay";               /* in zephyr/dts/arm/nordic/nrf52840.dtsi:345 */
		};

		/* node '/soc/egu@40016000' defined in zephyr/dts/arm/nordic/nrf52840.dtsi:348 */
		egu2: swi2: egu@40016000 {
			compatible = "nordic,nrf-egu",
			             "nordic,nrf-swi"; /* in zephyr/dts/arm/nordic/nrf52840.dtsi:349 */
			reg = < 0x40016000 0x1000 >;   /* in zephyr/dts/arm/nordic/nrf52840.dtsi:350 */
			interrupts = < 0x16 0x1 >;     /* in zephyr/dts/arm/nordic/nrf52840.dtsi:351 */
			status = "okay";               /* in zephyr/dts/arm/nordic/nrf52840.dtsi:352 */
		};

		/* node '/soc/egu@40017000' defined in zephyr/dts/arm/nordic/nrf52840.dtsi:355 */
		egu3: swi3: egu@40017000 {
			compatible = "nordic,nrf-egu",
			             "nordic,nrf-swi"; /* in zephyr/dts/arm/nordic/nrf52840.dtsi:356 */
			reg = < 0x40017000 0x1000 >;   /* in zephyr/dts/arm/nordic/nrf52840.dtsi:357 */
			interrupts = < 0x17 0x1 >;     /* in zephyr/dts/arm/nordic/nrf52840.dtsi:358 */
			status = "okay";               /* in zephyr/dts/arm/nordic/nrf52840.dtsi:359 */
		};

		/* node '/soc/egu@40018000' defined in zephyr/dts/arm/nordic/nrf52840.dtsi:362 */
		egu4: swi4: egu@40018000 {
			compatible = "nordic,nrf-egu",
			             "nordic,nrf-swi"; /* in zephyr/dts/arm/nordic/nrf52840.dtsi:363 */
			reg = < 0x40018000 0x1000 >;   /* in zephyr/dts/arm/nordic/nrf52840.dtsi:364 */
			interrupts = < 0x18 0x1 >;     /* in zephyr/dts/arm/nordic/nrf52840.dtsi:365 */
			status = "okay";               /* in zephyr/dts/arm/nordic/nrf52840.dtsi:366 */
		};

		/* node '/soc/egu@40019000' defined in zephyr/dts/arm/nordic/nrf52840.dtsi:369 */
		egu5: swi5: egu@40019000 {
			compatible = "nordic,nrf-egu",
			             "nordic,nrf-swi"; /* in zephyr/dts/arm/nordic/nrf52840.dtsi:370 */
			reg = < 0x40019000 0x1000 >;   /* in zephyr/dts/arm/nordic/nrf52840.dtsi:371 */
			interrupts = < 0x19 0x1 >;     /* in zephyr/dts/arm/nordic/nrf52840.dtsi:372 */
			status = "okay";               /* in zephyr/dts/arm/nordic/nrf52840.dtsi:373 */
		};

		/* node '/soc/timer@4001a000' defined in zephyr/dts/arm/nordic/nrf52840.dtsi:376 */
		timer3: timer@4001a000 {
			compatible = "nordic,nrf-timer"; /* in zephyr/dts/arm/nordic/nrf52840.dtsi:377 */
			status = "disabled";             /* in zephyr/dts/arm/nordic/nrf52840.dtsi:378 */
			reg = < 0x4001a000 0x1000 >;     /* in zephyr/dts/arm/nordic/nrf52840.dtsi:379 */
			cc-num = < 0x6 >;                /* in zephyr/dts/arm/nordic/nrf52840.dtsi:380 */
			max-bit-width = < 0x20 >;        /* in zephyr/dts/arm/nordic/nrf52840.dtsi:381 */
			interrupts = < 0x1a 0x1 >;       /* in zephyr/dts/arm/nordic/nrf52840.dtsi:382 */
			prescaler = < 0x0 >;             /* in zephyr/dts/arm/nordic/nrf52840.dtsi:383 */
		};

		/* node '/soc/timer@4001b000' defined in zephyr/dts/arm/nordic/nrf52840.dtsi:386 */
		timer4: timer@4001b000 {
			compatible = "nordic,nrf-timer"; /* in zephyr/dts/arm/nordic/nrf52840.dtsi:387 */
			status = "disabled";             /* in zephyr/dts/arm/nordic/nrf52840.dtsi:388 */
			reg = < 0x4001b000 0x1000 >;     /* in zephyr/dts/arm/nordic/nrf52840.dtsi:389 */
			cc-num = < 0x6 >;                /* in zephyr/dts/arm/nordic/nrf52840.dtsi:390 */
			max-bit-width = < 0x20 >;        /* in zephyr/dts/arm/nordic/nrf52840.dtsi:391 */
			interrupts = < 0x1b 0x1 >;       /* in zephyr/dts/arm/nordic/nrf52840.dtsi:392 */
			prescaler = < 0x0 >;             /* in zephyr/dts/arm/nordic/nrf52840.dtsi:393 */
		};

		/* node '/soc/pwm@4001c000' defined in zephyr/dts/arm/nordic/nrf52840.dtsi:396 */
		pwm0: pwm@4001c000 {
			compatible = "nordic,nrf-pwm"; /* in zephyr/dts/arm/nordic/nrf52840.dtsi:397 */
			reg = < 0x4001c000 0x1000 >;   /* in zephyr/dts/arm/nordic/nrf52840.dtsi:398 */
			interrupts = < 0x1c 0x1 >;     /* in zephyr/dts/arm/nordic/nrf52840.dtsi:399 */
			status = "okay";               /* in zephyr/boards/nordic/nrf52840dk/nrf52840dk_nrf52840.dts:219 */
			#pwm-cells = < 0x3 >;          /* in zephyr/dts/arm/nordic/nrf52840.dtsi:401 */
			pinctrl-0 = < &pwm0_default >; /* in zephyr/boards/nordic/nrf52840dk/nrf52840dk_nrf52840.dts:220 */
			pinctrl-1 = < &pwm0_sleep >;   /* in zephyr/boards/nordic/nrf52840dk/nrf52840dk_nrf52840.dts:221 */
			pinctrl-names = "default",
			                "sleep";       /* in zephyr/boards/nordic/nrf52840dk/nrf52840dk_nrf52840.dts:222 */
			phandle = < 0x19 >;            /* in zephyr/boards/nordic/nrf52840dk/nrf52840dk_nrf52840.dts:55 */
		};

		/* node '/soc/pdm@4001d000' defined in zephyr/dts/arm/nordic/nrf52840.dtsi:404 */
		pdm0: pdm@4001d000 {
			compatible = "nordic,nrf-pdm"; /* in zephyr/dts/arm/nordic/nrf52840.dtsi:405 */
			reg = < 0x4001d000 0x1000 >;   /* in zephyr/dts/arm/nordic/nrf52840.dtsi:406 */
			interrupts = < 0x1d 0x1 >;     /* in zephyr/dts/arm/nordic/nrf52840.dtsi:407 */
			status = "disabled";           /* in zephyr/dts/arm/nordic/nrf52840.dtsi:408 */
		};

		/* node '/soc/acl@4001e000' defined in zephyr/dts/arm/nordic/nrf52840.dtsi:411 */
		acl: acl@4001e000 {
			compatible = "nordic,nrf-acl"; /* in zephyr/dts/arm/nordic/nrf52840.dtsi:412 */
			reg = < 0x4001e000 0x1000 >;   /* in zephyr/dts/arm/nordic/nrf52840.dtsi:413 */
			status = "okay";               /* in zephyr/dts/arm/nordic/nrf52840.dtsi:414 */
		};

		/* node '/soc/flash-controller@4001e000' defined in zephyr/dts/arm/nordic/nrf52840.dtsi:417 */
		flash_controller: flash-controller@4001e000 {
			compatible = "nordic,nrf52-flash-controller"; /* in zephyr/dts/arm/nordic/nrf52840.dtsi:418 */
			reg = < 0x4001e000 0x1000 >;                  /* in zephyr/dts/arm/nordic/nrf52840.dtsi:419 */
			partial-erase;                                /* in zephyr/dts/arm/nordic/nrf52840.dtsi:420 */
			#address-cells = < 0x1 >;                     /* in zephyr/dts/arm/nordic/nrf52840.dtsi:422 */
			#size-cells = < 0x1 >;                        /* in zephyr/dts/arm/nordic/nrf52840.dtsi:423 */

			/* node '/soc/flash-controller@4001e000/flash@0' defined in zephyr/dts/arm/nordic/nrf52840.dtsi:426 */
			flash0: flash@0 {
				compatible = "soc-nv-flash";   /* in zephyr/dts/arm/nordic/nrf52840.dtsi:427 */
				erase-block-size = < 0x1000 >; /* in zephyr/dts/arm/nordic/nrf52840.dtsi:428 */
				write-block-size = < 0x4 >;    /* in zephyr/dts/arm/nordic/nrf52840.dtsi:429 */
				reg = < 0x0 0x100000 >;        /* in zephyr/dts/arm/nordic/nrf52840_qiaa.dtsi:11 */

				/* node '/soc/flash-controller@4001e000/flash@0/partitions' defined in zephyr/dts/vendor/nordic/nrf52840_partition.dtsi:16 */
				partitions {
					compatible = "fixed-partitions"; /* in zephyr/dts/vendor/nordic/nrf52840_partition.dtsi:17 */
					#address-cells = < 0x1 >;        /* in zephyr/dts/vendor/nordic/nrf52840_partition.dtsi:18 */
					#size-cells = < 0x1 >;           /* in zephyr/dts/vendor/nordic/nrf52840_partition.dtsi:19 */

					/* node '/soc/flash-controller@4001e000/flash@0/partitions/partition@0' defined in zephyr/dts/vendor/nordic/nrf52840_partition.dtsi:21 */
					boot_partition: partition@0 {
						label = "mcuboot";    /* in zephyr/dts/vendor/nordic/nrf52840_partition.dtsi:22 */
						reg = < 0x0 0xc000 >; /* in zephyr/dts/vendor/nordic/nrf52840_partition.dtsi:23 */
					};

					/* node '/soc/flash-controller@4001e000/flash@0/partitions/partition@c000' defined in zephyr/dts/vendor/nordic/nrf52840_partition.dtsi:26 */
					slot0_partition: partition@c000 {
						label = "image-0";        /* in zephyr/dts/vendor/nordic/nrf52840_partition.dtsi:27 */
						reg = < 0xc000 0x76000 >; /* in zephyr/dts/vendor/nordic/nrf52840_partition.dtsi:28 */
					};

					/* node '/soc/flash-controller@4001e000/flash@0/partitions/partition@82000' defined in zephyr/dts/vendor/nordic/nrf52840_partition.dtsi:31 */
					slot1_partition: partition@82000 {
						label = "image-1";         /* in zephyr/dts/vendor/nordic/nrf52840_partition.dtsi:32 */
						reg = < 0x82000 0x76000 >; /* in zephyr/dts/vendor/nordic/nrf52840_partition.dtsi:33 */
					};

					/* node '/soc/flash-controller@4001e000/flash@0/partitions/partition@f8000' defined in zephyr/dts/vendor/nordic/nrf52840_partition.dtsi:45 */
					storage_partition: partition@f8000 {
						label = "storage";        /* in zephyr/dts/vendor/nordic/nrf52840_partition.dtsi:46 */
						reg = < 0xf8000 0x8000 >; /* in zephyr/dts/vendor/nordic/nrf52840_partition.dtsi:47 */
					};
				};
			};
		};

		/* node '/soc/ppi@4001f000' defined in zephyr/dts/arm/nordic/nrf52840.dtsi:433 */
		ppi: ppi@4001f000 {
			compatible = "nordic,nrf-ppi"; /* in zephyr/dts/arm/nordic/nrf52840.dtsi:434 */
			reg = < 0x4001f000 0x1000 >;   /* in zephyr/dts/arm/nordic/nrf52840.dtsi:435 */
			status = "okay";               /* in zephyr/dts/arm/nordic/nrf52840.dtsi:436 */
		};

		/* node '/soc/mwu@40020000' defined in zephyr/dts/arm/nordic/nrf52840.dtsi:439 */
		mwu: mwu@40020000 {
			compatible = "nordic,nrf-mwu"; /* in zephyr/dts/arm/nordic/nrf52840.dtsi:440 */
			reg = < 0x40020000 0x1000 >;   /* in zephyr/dts/arm/nordic/nrf52840.dtsi:441 */
			status = "okay";               /* in zephyr/dts/arm/nordic/nrf52840.dtsi:442 */
		};

		/* node '/soc/pwm@40021000' defined in zephyr/dts/arm/nordic/nrf52840.dtsi:445 */
		pwm1: pwm@40021000 {
			compatible = "nordic,nrf-pwm"; /* in zephyr/dts/arm/nordic/nrf52840.dtsi:446 */
			reg = < 0x40021000 0x1000 >;   /* in zephyr/dts/arm/nordic/nrf52840.dtsi:447 */
			interrupts = < 0x21 0x1 >;     /* in zephyr/dts/arm/nordic/nrf52840.dtsi:448 */
			status = "disabled";           /* in zephyr/dts/arm/nordic/nrf52840.dtsi:449 */
			#pwm-cells = < 0x3 >;          /* in zephyr/dts/arm/nordic/nrf52840.dtsi:450 */
		};

		/* node '/soc/pwm@40022000' defined in zephyr/dts/arm/nordic/nrf52840.dtsi:453 */
		pwm2: pwm@40022000 {
			compatible = "nordic,nrf-pwm"; /* in zephyr/dts/arm/nordic/nrf52840.dtsi:454 */
			reg = < 0x40022000 0x1000 >;   /* in zephyr/dts/arm/nordic/nrf52840.dtsi:455 */
			interrupts = < 0x22 0x1 >;     /* in zephyr/dts/arm/nordic/nrf52840.dtsi:456 */
			status = "disabled";           /* in zephyr/dts/arm/nordic/nrf52840.dtsi:457 */
			#pwm-cells = < 0x3 >;          /* in zephyr/dts/arm/nordic/nrf52840.dtsi:458 */
		};

		/* node '/soc/spi@40023000' defined in zephyr/dts/arm/nordic/nrf52840.dtsi:461 */
		spi2: spi@40023000 {
			compatible = "nordic,nrf-spi";  /* in zephyr/boards/nordic/nrf52840dk/nrf52840dk_nrf52840.dts:243 */
			#address-cells = < 0x1 >;       /* in zephyr/dts/arm/nordic/nrf52840.dtsi:470 */
			#size-cells = < 0x0 >;          /* in zephyr/dts/arm/nordic/nrf52840.dtsi:471 */
			reg = < 0x40023000 0x1000 >;    /* in zephyr/dts/arm/nordic/nrf52840.dtsi:472 */
			interrupts = < 0x23 0x1 >;      /* in zephyr/dts/arm/nordic/nrf52840.dtsi:473 */
			max-frequency = < 0x7a1200 >;   /* in zephyr/dts/arm/nordic/nrf52840.dtsi:474 */
			easydma-maxcnt-bits = < 0x10 >; /* in zephyr/dts/arm/nordic/nrf52840.dtsi:475 */
			status = "disabled";            /* in zephyr/boards/nordic/nrf52840dk/nrf52840dk_nrf52840.dts:244 */
			pinctrl-0 = < &spi2_default >;  /* in zephyr/boards/nordic/nrf52840dk/nrf52840dk_nrf52840.dts:245 */
			pinctrl-1 = < &spi2_sleep >;    /* in zephyr/boards/nordic/nrf52840dk/nrf52840dk_nrf52840.dts:246 */
			pinctrl-names = "default",
			                "sleep";        /* in zephyr/boards/nordic/nrf52840dk/nrf52840dk_nrf52840.dts:247 */
		};

		/* node '/soc/rtc@40024000' defined in zephyr/dts/arm/nordic/nrf52840.dtsi:479 */
		rtc2: rtc@40024000 {
			compatible = "nordic,nrf-rtc"; /* in zephyr/dts/arm/nordic/nrf52840.dtsi:480 */
			reg = < 0x40024000 0x1000 >;   /* in zephyr/dts/arm/nordic/nrf52840.dtsi:481 */
			cc-num = < 0x4 >;              /* in zephyr/dts/arm/nordic/nrf52840.dtsi:482 */
			interrupts = < 0x24 0x1 >;     /* in zephyr/dts/arm/nordic/nrf52840.dtsi:483 */
			status = "disabled";           /* in zephyr/dts/arm/nordic/nrf52840.dtsi:484 */
			clock-frequency = < 0x8000 >;  /* in zephyr/dts/arm/nordic/nrf52840.dtsi:485 */
			prescaler = < 0x1 >;           /* in zephyr/dts/arm/nordic/nrf52840.dtsi:486 */
		};

		/* node '/soc/i2s@40025000' defined in zephyr/dts/arm/nordic/nrf52840.dtsi:489 */
		i2s0: i2s@40025000 {
			compatible = "nordic,nrf-i2s"; /* in zephyr/dts/arm/nordic/nrf52840.dtsi:490 */
			#address-cells = < 0x1 >;      /* in zephyr/dts/arm/nordic/nrf52840.dtsi:491 */
			#size-cells = < 0x0 >;         /* in zephyr/dts/arm/nordic/nrf52840.dtsi:492 */
			reg = < 0x40025000 0x1000 >;   /* in zephyr/dts/arm/nordic/nrf52840.dtsi:493 */
			interrupts = < 0x25 0x1 >;     /* in zephyr/dts/arm/nordic/nrf52840.dtsi:494 */
			status = "disabled";           /* in zephyr/dts/arm/nordic/nrf52840.dtsi:495 */
		};

		/* node '/soc/usbd@40027000' defined in zephyr/dts/arm/nordic/nrf52840.dtsi:498 */
		usbd: zephyr_udc0: usbd@40027000 {
			compatible = "nordic,nrf-usbd"; /* in zephyr/boards/nordic/nrf52840dk/nrf52840dk_nrf52840.dts:291 */
			reg = < 0x40027000 0x1000 >;    /* in zephyr/dts/arm/nordic/nrf52840.dtsi:500 */
			interrupts = < 0x27 0x1 >;      /* in zephyr/dts/arm/nordic/nrf52840.dtsi:501 */
			num-bidir-endpoints = < 0x1 >;  /* in zephyr/dts/arm/nordic/nrf52840.dtsi:502 */
			num-in-endpoints = < 0x7 >;     /* in zephyr/dts/arm/nordic/nrf52840.dtsi:503 */
			num-out-endpoints = < 0x7 >;    /* in zephyr/dts/arm/nordic/nrf52840.dtsi:504 */
			num-isoin-endpoints = < 0x1 >;  /* in zephyr/dts/arm/nordic/nrf52840.dtsi:505 */
			num-isoout-endpoints = < 0x1 >; /* in zephyr/dts/arm/nordic/nrf52840.dtsi:506 */
			status = "okay";                /* in zephyr/boards/nordic/nrf52840dk/nrf52840dk_nrf52840.dts:292 */

			/* node '/soc/usbd@40027000/cdc_acm_uart0' defined in app/boards/nrf52840dk_nrf52840.overlay:158 */
			cdc_acm_uart0: cdc_acm_uart0 {
				compatible = "zephyr,cdc-acm-uart"; /* in app/boards/nrf52840dk_nrf52840.overlay:159 */
			};
		};

		/* node '/soc/uart@40028000' defined in zephyr/dts/arm/nordic/nrf52840.dtsi:510 */
		uart1: arduino_serial: uart@40028000 {
			compatible = "nordic,nrf-uarte"; /* in zephyr/dts/arm/nordic/nrf52840.dtsi:511 */
			reg = < 0x40028000 0x1000 >;     /* in zephyr/dts/arm/nordic/nrf52840.dtsi:512 */
			interrupts = < 0x28 0x1 >;       /* in zephyr/dts/arm/nordic/nrf52840.dtsi:513 */
			status = "disabled";             /* in zephyr/dts/arm/nordic/nrf52840.dtsi:514 */
			current-speed = < 0x1c200 >;     /* in zephyr/boards/nordic/nrf52840dk/nrf52840dk_nrf52840.dts:195 */
			pinctrl-0 = < &uart1_default >;  /* in zephyr/boards/nordic/nrf52840dk/nrf52840dk_nrf52840.dts:196 */
			pinctrl-1 = < &uart1_sleep >;    /* in zephyr/boards/nordic/nrf52840dk/nrf52840dk_nrf52840.dts:197 */
			pinctrl-names = "default",
			                "sleep";         /* in zephyr/boards/nordic/nrf52840dk/nrf52840dk_nrf52840.dts:198 */
		};

		/* node '/soc/qspi@40029000' defined in zephyr/dts/arm/nordic/nrf52840.dtsi:517 */
		qspi: qspi@40029000 {
			compatible = "nordic,nrf-qspi"; /* in zephyr/dts/arm/nordic/nrf52840.dtsi:518 */
			#address-cells = < 0x1 >;       /* in zephyr/dts/arm/nordic/nrf52840.dtsi:519 */
			#size-cells = < 0x0 >;          /* in zephyr/dts/arm/nordic/nrf52840.dtsi:520 */
			reg = < 0x40029000 0x1000 >,
			      < 0x12000000 0x8000000 >; /* in zephyr/dts/arm/nordic/nrf52840.dtsi:521 */
			reg-names = "qspi",
			            "qspi_mm";          /* in zephyr/dts/arm/nordic/nrf52840.dtsi:522 */
			interrupts = < 0x29 0x1 >;      /* in zephyr/dts/arm/nordic/nrf52840.dtsi:523 */
			status = "disabled";            /* in app/boards/nrf52840dk_nrf52840.overlay:67 */
			pinctrl-0 = < &qspi_default >;  /* in zephyr/boards/nordic/nrf52840dk/nrf52840dk_nrf52840.dts:252 */
			pinctrl-1 = < &qspi_sleep >;    /* in zephyr/boards/nordic/nrf52840dk/nrf52840dk_nrf52840.dts:253 */
			pinctrl-names = "default",
			                "sleep";        /* in zephyr/boards/nordic/nrf52840dk/nrf52840dk_nrf52840.dts:254 */

			/* node '/soc/qspi@40029000/mx25r6435f@0' defined in zephyr/boards/nordic/nrf52840dk/nrf52840dk_nrf52840.dts:256 */
			mx25r64: mx25r6435f@0 {
				compatible = "nordic,qspi-nor";                                                                                                                                                                                 /* in zephyr/boards/nordic/nrf52840dk/nrf52840dk_nrf52840.dts:257 */
				reg = < 0x0 >;                                                                                                                                                                                                  /* in zephyr/boards/nordic/nrf52840dk/nrf52840dk_nrf52840.dts:258 */
				writeoc = "pp4io";                                                                                                                                                                                              /* in zephyr/boards/nordic/nrf52840dk/nrf52840dk_nrf52840.dts:260 */
				readoc = "read4io";                                                                                                                                                                                             /* in zephyr/boards/nordic/nrf52840dk/nrf52840dk_nrf52840.dts:262 */
				sck-frequency = < 0x7a1200 >;                                                                                                                                                                                   /* in zephyr/boards/nordic/nrf52840dk/nrf52840dk_nrf52840.dts:263 */
				jedec-id = [ C2 28 17 ];                                                                                                                                                                                        /* in zephyr/boards/nordic/nrf52840dk/nrf52840dk_nrf52840.dts:264 */
				sfdp-bfp = [ E5 20 F1 FF FF FF FF 03 44 EB 08 6B 08 3B 04 BB EE FF FF FF FF FF 00 FF FF FF 00 FF 0C 20 0F 52 10 D8 00 FF 23 72 F5 00 82 ED 04 CC 44 83 68 44 30 B0 30 B0 F7 C4 D5 5C 00 BE 29 FF F0 D0 FF FF ]; /* in zephyr/boards/nordic/nrf52840dk/nrf52840dk_nrf52840.dts:265 */
				size = < 0x4000000 >;                                                                                                                                                                                           /* in zephyr/boards/nordic/nrf52840dk/nrf52840dk_nrf52840.dts:271 */
				has-dpd;                                                                                                                                                                                                        /* in zephyr/boards/nordic/nrf52840dk/nrf52840dk_nrf52840.dts:272 */
				t-enter-dpd = < 0x2710 >;                                                                                                                                                                                       /* in zephyr/boards/nordic/nrf52840dk/nrf52840dk_nrf52840.dts:273 */
				t-exit-dpd = < 0x88b8 >;                                                                                                                                                                                        /* in zephyr/boards/nordic/nrf52840dk/nrf52840dk_nrf52840.dts:274 */
			};
		};

		/* node '/soc/pwm@4002d000' defined in zephyr/dts/arm/nordic/nrf52840.dtsi:527 */
		pwm3: pwm@4002d000 {
			compatible = "nordic,nrf-pwm"; /* in zephyr/dts/arm/nordic/nrf52840.dtsi:528 */
			reg = < 0x4002d000 0x1000 >;   /* in zephyr/dts/arm/nordic/nrf52840.dtsi:529 */
			interrupts = < 0x2d 0x1 >;     /* in zephyr/dts/arm/nordic/nrf52840.dtsi:530 */
			status = "disabled";           /* in zephyr/dts/arm/nordic/nrf52840.dtsi:531 */
			#pwm-cells = < 0x3 >;          /* in zephyr/dts/arm/nordic/nrf52840.dtsi:532 */
		};

		/* node '/soc/spi@4002f000' defined in zephyr/dts/arm/nordic/nrf52840.dtsi:535 */
		spi3: arduino_spi: spi@4002f000 {
			compatible = "nordic,nrf-spim"; /* in app/boards/nrf52840dk_nrf52840.overlay:141 */
			#address-cells = < 0x1 >;       /* in zephyr/dts/arm/nordic/nrf52840.dtsi:537 */
			#size-cells = < 0x0 >;          /* in zephyr/dts/arm/nordic/nrf52840.dtsi:538 */
			reg = < 0x4002f000 0x1000 >;    /* in zephyr/dts/arm/nordic/nrf52840.dtsi:539 */
			interrupts = < 0x2f 0x1 >;      /* in zephyr/dts/arm/nordic/nrf52840.dtsi:540 */
			max-frequency = < 0x1e84800 >;  /* in app/boards/nrf52840dk_nrf52840.overlay:143 */
			easydma-maxcnt-bits = < 0x10 >; /* in zephyr/dts/arm/nordic/nrf52840.dtsi:542 */
			rx-delay-supported;             /* in zephyr/dts/arm/nordic/nrf52840.dtsi:543 */
			rx-delay = < 0x2 >;             /* in zephyr/dts/arm/nordic/nrf52840.dtsi:544 */
			status = "okay";                /* in app/boards/nrf52840dk_nrf52840.overlay:142 */
			cs-gpios = < &gpio0 0x1f 0x1 >; /* in app/boards/nrf52840dk_nrf52840.overlay:147 */
			pinctrl-0 = < &spi3_default >;  /* in app/boards/nrf52840dk_nrf52840.overlay:144 */
			pinctrl-1 = < &spi3_sleep >;    /* in app/boards/nrf52840dk_nrf52840.overlay:145 */
			pinctrl-names = "default",
			                "sleep";        /* in app/boards/nrf52840dk_nrf52840.overlay:146 */

			/* node '/soc/spi@4002f000/imu_spi@0' defined in app/boards/nrf52840dk_nrf52840.overlay:149 */
			imu_spi: imu_spi@0 {
				compatible = "vnd,spi-device";     /* in app/boards/nrf52840dk_nrf52840.overlay:150 */
				spi-max-frequency = < 0x1e84800 >; /* in app/boards/nrf52840dk_nrf52840.overlay:151 */
				label = "imu-spi";                 /* in app/boards/nrf52840dk_nrf52840.overlay:152 */
				reg = < 0x0 >;                     /* in app/boards/nrf52840dk_nrf52840.overlay:153 */
			};
		};

		/* node '/soc/gpio@50000000' defined in zephyr/dts/arm/nordic/nrf52840.dtsi:548 */
		gpio0: gpio@50000000 {
			compatible = "nordic,nrf-gpio";              /* in zephyr/dts/arm/nordic/nrf52840.dtsi:549 */
			gpio-controller;                             /* in zephyr/dts/arm/nordic/nrf52840.dtsi:550 */
			reg = < 0x50000000 0x200 0x50000500 0x300 >; /* in zephyr/dts/arm/nordic/nrf52840.dtsi:551 */
			#gpio-cells = < 0x2 >;                       /* in zephyr/dts/arm/nordic/nrf52840.dtsi:553 */
			status = "okay";                             /* in zephyr/boards/nordic/nrf52840dk/nrf52840dk_nrf52840.dts:170 */
			port = < 0x0 >;                              /* in zephyr/dts/arm/nordic/nrf52840.dtsi:555 */
			gpiote-instance = < &gpiote >;               /* in zephyr/dts/arm/nordic/nrf52840.dtsi:556 */
			gpio-reserved-ranges = < 0x0 0x2 >,
			                       < 0x6 0x1 >,
			                       < 0x8 0x3 >,
			                       < 0x11 0x7 >;         /* in zephyr/boards/nordic/nrf52840dk/nrf52840dk_nrf52840.dts:171 */
			gpio-line-names = "XL1",
			                  "XL2",
			                  "AREF",
			                  "A0",
			                  "A1",
			                  "RTS",
			                  "TXD",
			                  "CTS",
			                  "RXD",
			                  "NFC1",
			                  "NFC2",
			                  "BUTTON1",
			                  "BUTTON2",
			                  "LED1",
			                  "LED2",
			                  "LED3",
			                  "LED4",
			                  "QSPI CS",
			                  "RESET",
			                  "QSPI CLK",
			                  "QSPI DIO0",
			                  "QSPI DIO1",
			                  "QSPI DIO2",
			                  "QSPI DIO3",
			                  "BUTTON3",
			                  "BUTTON4",
			                  "SDA",
			                  "SCL",
			                  "A2",
			                  "A3",
			                  "A4",
			                  "A5";                      /* in zephyr/boards/nordic/nrf52840dk/nrf52840dk_nrf52840.dts:172 */
			phandle = < 0x14 >;                          /* in app/boards/nrf52840dk_nrf52840.overlay:147 */
		};

		/* node '/soc/gpio@50000300' defined in zephyr/dts/arm/nordic/nrf52840.dtsi:559 */
		gpio1: gpio@50000300 {
			compatible = "nordic,nrf-gpio";              /* in zephyr/dts/arm/nordic/nrf52840.dtsi:560 */
			gpio-controller;                             /* in zephyr/dts/arm/nordic/nrf52840.dtsi:561 */
			reg = < 0x50000300 0x200 0x50000800 0x300 >; /* in zephyr/dts/arm/nordic/nrf52840.dtsi:562 */
			#gpio-cells = < 0x2 >;                       /* in zephyr/dts/arm/nordic/nrf52840.dtsi:564 */
			ngpios = < 0x10 >;                           /* in zephyr/dts/arm/nordic/nrf52840.dtsi:565 */
			status = "okay";                             /* in zephyr/boards/nordic/nrf52840dk/nrf52840dk_nrf52840.dts:180 */
			port = < 0x1 >;                              /* in zephyr/dts/arm/nordic/nrf52840.dtsi:567 */
			gpiote-instance = < &gpiote >;               /* in zephyr/dts/arm/nordic/nrf52840.dtsi:568 */
			gpio-line-names = "",
			                  "D0",
			                  "D1",
			                  "D2",
			                  "D3",
			                  "D4",
			                  "D5",
			                  "D6",
			                  "D7",
			                  "",
			                  "D8",
			                  "D9",
			                  "D10",
			                  "D11",
			                  "D12",
			                  "D13";                     /* in zephyr/boards/nordic/nrf52840dk/nrf52840dk_nrf52840.dts:181 */
			phandle = < 0x1a >;                          /* in app/boards/nrf52840dk_nrf52840.overlay:96 */
		};

		/* node '/soc/crypto@5002a000' defined in zephyr/dts/arm/nordic/nrf52840.dtsi:571 */
		cryptocell: crypto@5002a000 {
			compatible = "arm,cryptocell-310"; /* in zephyr/dts/arm/nordic/nrf52840.dtsi:572 */
			reg = < 0x5002a000 0x1000 >,
			      < 0x5002b000 0x1000 >;       /* in zephyr/dts/arm/nordic/nrf52840.dtsi:573 */
			reg-names = "wrapper",
			            "core";                /* in zephyr/dts/arm/nordic/nrf52840.dtsi:574 */
			interrupts = < 0x2a 0x1 >;         /* in zephyr/dts/arm/nordic/nrf52840.dtsi:575 */
			status = "okay";                   /* in zephyr/dts/arm/nordic/nrf52840.dtsi:576 */
		};
	};

	/* node '/pin-controller' defined in zephyr/dts/vendor/nordic/nrf_common.dtsi:25 */
	pinctrl: pin-controller {
		compatible = "nordic,nrf-pinctrl"; /* in zephyr/dts/vendor/nordic/nrf_common.dtsi:30 */

		/* node '/pin-controller/uart0_default' defined in zephyr/boards/nordic/nrf52840dk/nrf52840dk_nrf52840-pinctrl.dtsi:7 */
		uart0_default: uart0_default {
			phandle = < 0x2 >; /* in zephyr/boards/nordic/nrf52840dk/nrf52840dk_nrf52840.dts:189 */

			/* node '/pin-controller/uart0_default/group1' defined in zephyr/boards/nordic/nrf52840dk/nrf52840dk_nrf52840-pinctrl.dtsi:8 */
			group1 {
				psels = < 0x6 >,
				        < 0x2000005 >; /* in zephyr/boards/nordic/nrf52840dk/nrf52840dk_nrf52840-pinctrl.dtsi:9 */
			};

			/* node '/pin-controller/uart0_default/group2' defined in zephyr/boards/nordic/nrf52840dk/nrf52840dk_nrf52840-pinctrl.dtsi:13 */
			group2 {
				psels = < 0x1000008 >,
				        < 0x3000007 >; /* in zephyr/boards/nordic/nrf52840dk/nrf52840dk_nrf52840-pinctrl.dtsi:14 */
				bias-pull-up;          /* in zephyr/boards/nordic/nrf52840dk/nrf52840dk_nrf52840-pinctrl.dtsi:16 */
			};
		};

		/* node '/pin-controller/uart0_sleep' defined in zephyr/boards/nordic/nrf52840dk/nrf52840dk_nrf52840-pinctrl.dtsi:20 */
		uart0_sleep: uart0_sleep {
			phandle = < 0x3 >; /* in zephyr/boards/nordic/nrf52840dk/nrf52840dk_nrf52840.dts:190 */

			/* node '/pin-controller/uart0_sleep/group1' defined in zephyr/boards/nordic/nrf52840dk/nrf52840dk_nrf52840-pinctrl.dtsi:21 */
			group1 {
				psels = < 0x6 >,
				        < 0x1000008 >,
				        < 0x2000005 >,
				        < 0x3000007 >; /* in zephyr/boards/nordic/nrf52840dk/nrf52840dk_nrf52840-pinctrl.dtsi:22 */
				low-power-enable;      /* in zephyr/boards/nordic/nrf52840dk/nrf52840dk_nrf52840-pinctrl.dtsi:26 */
			};
		};

		/* node '/pin-controller/uart1_default' defined in zephyr/boards/nordic/nrf52840dk/nrf52840dk_nrf52840-pinctrl.dtsi:30 */
		uart1_default: uart1_default {
			phandle = < 0x10 >; /* in zephyr/boards/nordic/nrf52840dk/nrf52840dk_nrf52840.dts:196 */

			/* node '/pin-controller/uart1_default/group1' defined in zephyr/boards/nordic/nrf52840dk/nrf52840dk_nrf52840-pinctrl.dtsi:31 */
			group1 {
				psels = < 0x1000021 >; /* in zephyr/boards/nordic/nrf52840dk/nrf52840dk_nrf52840-pinctrl.dtsi:32 */
				bias-pull-up;          /* in zephyr/boards/nordic/nrf52840dk/nrf52840dk_nrf52840-pinctrl.dtsi:33 */
			};

			/* node '/pin-controller/uart1_default/group2' defined in zephyr/boards/nordic/nrf52840dk/nrf52840dk_nrf52840-pinctrl.dtsi:36 */
			group2 {
				psels = < 0x22 >; /* in zephyr/boards/nordic/nrf52840dk/nrf52840dk_nrf52840-pinctrl.dtsi:37 */
			};
		};

		/* node '/pin-controller/uart1_sleep' defined in zephyr/boards/nordic/nrf52840dk/nrf52840dk_nrf52840-pinctrl.dtsi:41 */
		uart1_sleep: uart1_sleep {
			phandle = < 0x11 >; /* in zephyr/boards/nordic/nrf52840dk/nrf52840dk_nrf52840.dts:197 */

			/* node '/pin-controller/uart1_sleep/group1' defined in zephyr/boards/nordic/nrf52840dk/nrf52840dk_nrf52840-pinctrl.dtsi:42 */
			group1 {
				psels = < 0x1000021 >,
				        < 0x22 >;      /* in zephyr/boards/nordic/nrf52840dk/nrf52840dk_nrf52840-pinctrl.dtsi:43 */
				low-power-enable;      /* in zephyr/boards/nordic/nrf52840dk/nrf52840dk_nrf52840-pinctrl.dtsi:45 */
			};
		};

		/* node '/pin-controller/i2c0_default' defined in zephyr/boards/nordic/nrf52840dk/nrf52840dk_nrf52840-pinctrl.dtsi:49 */
		i2c0_default: i2c0_default {
			phandle = < 0x4 >; /* in zephyr/boards/nordic/nrf52840dk/nrf52840dk_nrf52840.dts:204 */

			/* node '/pin-controller/i2c0_default/group1' defined in zephyr/boards/nordic/nrf52840dk/nrf52840dk_nrf52840-pinctrl.dtsi:50 */
			group1 {
				psels = < 0xc00001a >,
				        < 0xb00001b >; /* in zephyr/boards/nordic/nrf52840dk/nrf52840dk_nrf52840-pinctrl.dtsi:51 */
				bias-disable;          /* in app/boards/nrf52840dk_nrf52840.overlay:27 */
			};
		};

		/* node '/pin-controller/i2c0_sleep' defined in zephyr/boards/nordic/nrf52840dk/nrf52840dk_nrf52840-pinctrl.dtsi:56 */
		i2c0_sleep: i2c0_sleep {
			phandle = < 0x5 >; /* in zephyr/boards/nordic/nrf52840dk/nrf52840dk_nrf52840.dts:205 */

			/* node '/pin-controller/i2c0_sleep/group1' defined in zephyr/boards/nordic/nrf52840dk/nrf52840dk_nrf52840-pinctrl.dtsi:57 */
			group1 {
				psels = < 0xc00001a >,
				        < 0xb00001b >; /* in zephyr/boards/nordic/nrf52840dk/nrf52840dk_nrf52840-pinctrl.dtsi:58 */
				low-power-enable;      /* in zephyr/boards/nordic/nrf52840dk/nrf52840dk_nrf52840-pinctrl.dtsi:60 */
				bias-disable;          /* in app/boards/nrf52840dk_nrf52840.overlay:33 */
			};
		};

		/* node '/pin-controller/i2c1_default' defined in zephyr/boards/nordic/nrf52840dk/nrf52840dk_nrf52840-pinctrl.dtsi:64 */
		i2c1_default: i2c1_default {
			phandle = < 0x8 >; /* in zephyr/boards/nordic/nrf52840dk/nrf52840dk_nrf52840.dts:213 */

			/* node '/pin-controller/i2c1_default/group1' defined in zephyr/boards/nordic/nrf52840dk/nrf52840dk_nrf52840-pinctrl.dtsi:65 */
			group1 {
				psels = < 0xc00001e >,
				        < 0xb00001f >; /* in zephyr/boards/nordic/nrf52840dk/nrf52840dk_nrf52840-pinctrl.dtsi:66 */
			};
		};

		/* node '/pin-controller/i2c1_sleep' defined in zephyr/boards/nordic/nrf52840dk/nrf52840dk_nrf52840-pinctrl.dtsi:71 */
		i2c1_sleep: i2c1_sleep {
			phandle = < 0x9 >; /* in zephyr/boards/nordic/nrf52840dk/nrf52840dk_nrf52840.dts:214 */

			/* node '/pin-controller/i2c1_sleep/group1' defined in zephyr/boards/nordic/nrf52840dk/nrf52840dk_nrf52840-pinctrl.dtsi:72 */
			group1 {
				psels = < 0xc00001e >,
				        < 0xb00001f >; /* in zephyr/boards/nordic/nrf52840dk/nrf52840dk_nrf52840-pinctrl.dtsi:73 */
				low-power-enable;      /* in zephyr/boards/nordic/nrf52840dk/nrf52840dk_nrf52840-pinctrl.dtsi:75 */
			};
		};

		/* node '/pin-controller/pwm0_default' defined in zephyr/boards/nordic/nrf52840dk/nrf52840dk_nrf52840-pinctrl.dtsi:79 */
		pwm0_default: pwm0_default {
			phandle = < 0xc >; /* in zephyr/boards/nordic/nrf52840dk/nrf52840dk_nrf52840.dts:220 */

			/* node '/pin-controller/pwm0_default/group1' defined in zephyr/boards/nordic/nrf52840dk/nrf52840dk_nrf52840-pinctrl.dtsi:80 */
			group1 {
				psels = < 0x1600000d >,
				        < 0x1700000e >,
				        < 0x1800000f >;      /* in app/boards/nrf52840dk_nrf52840.overlay:9 */
				nordic,invert;               /* in app/boards/nrf52840dk_nrf52840.overlay:13 */
				nordic,drive-mode = < 0x4 >; /* in app/boards/nrf52840dk_nrf52840.overlay:12 */
			};
		};

		/* node '/pin-controller/pwm0_sleep' defined in zephyr/boards/nordic/nrf52840dk/nrf52840dk_nrf52840-pinctrl.dtsi:86 */
		pwm0_sleep: pwm0_sleep {
			phandle = < 0xd >; /* in zephyr/boards/nordic/nrf52840dk/nrf52840dk_nrf52840.dts:221 */

			/* node '/pin-controller/pwm0_sleep/group1' defined in zephyr/boards/nordic/nrf52840dk/nrf52840dk_nrf52840-pinctrl.dtsi:87 */
			group1 {
				psels = < 0x1600000d >,
				        < 0x1700000e >,
				        < 0x1800000f >; /* in app/boards/nrf52840dk_nrf52840.overlay:19 */
				low-power-enable;       /* in zephyr/boards/nordic/nrf52840dk/nrf52840dk_nrf52840-pinctrl.dtsi:89 */
			};
		};

		/* node '/pin-controller/spi0_default' defined in zephyr/boards/nordic/nrf52840dk/nrf52840dk_nrf52840-pinctrl.dtsi:93 */
		spi0_default: spi0_default {
			phandle = < 0x6 >; /* in zephyr/boards/nordic/nrf52840dk/nrf52840dk_nrf52840.dts:229 */

			/* node '/pin-controller/spi0_default/group1' defined in zephyr/boards/nordic/nrf52840dk/nrf52840dk_nrf52840-pinctrl.dtsi:94 */
			group1 {
				psels = < 0x400001b >,
				        < 0x500001a >,
				        < 0x600001d >; /* in zephyr/boards/nordic/nrf52840dk/nrf52840dk_nrf52840-pinctrl.dtsi:95 */
			};
		};

		/* node '/pin-controller/spi0_sleep' defined in zephyr/boards/nordic/nrf52840dk/nrf52840dk_nrf52840-pinctrl.dtsi:101 */
		spi0_sleep: spi0_sleep {
			phandle = < 0x7 >; /* in zephyr/boards/nordic/nrf52840dk/nrf52840dk_nrf52840.dts:230 */

			/* node '/pin-controller/spi0_sleep/group1' defined in zephyr/boards/nordic/nrf52840dk/nrf52840dk_nrf52840-pinctrl.dtsi:102 */
			group1 {
				psels = < 0x400001b >,
				        < 0x500001a >,
				        < 0x600001d >; /* in zephyr/boards/nordic/nrf52840dk/nrf52840dk_nrf52840-pinctrl.dtsi:103 */
				low-power-enable;      /* in zephyr/boards/nordic/nrf52840dk/nrf52840dk_nrf52840-pinctrl.dtsi:106 */
			};
		};

		/* node '/pin-controller/spi1_default' defined in zephyr/boards/nordic/nrf52840dk/nrf52840dk_nrf52840-pinctrl.dtsi:110 */
		spi1_default: spi1_default {
			phandle = < 0xa >; /* in zephyr/boards/nordic/nrf52840dk/nrf52840dk_nrf52840.dts:237 */

			/* node '/pin-controller/spi1_default/group1' defined in zephyr/boards/nordic/nrf52840dk/nrf52840dk_nrf52840-pinctrl.dtsi:111 */
			group1 {
				psels = < 0x400001f >,
				        < 0x500001e >,
				        < 0x6000028 >; /* in zephyr/boards/nordic/nrf52840dk/nrf52840dk_nrf52840-pinctrl.dtsi:112 */
			};
		};

		/* node '/pin-controller/spi1_sleep' defined in zephyr/boards/nordic/nrf52840dk/nrf52840dk_nrf52840-pinctrl.dtsi:118 */
		spi1_sleep: spi1_sleep {
			phandle = < 0xb >; /* in zephyr/boards/nordic/nrf52840dk/nrf52840dk_nrf52840.dts:238 */

			/* node '/pin-controller/spi1_sleep/group1' defined in zephyr/boards/nordic/nrf52840dk/nrf52840dk_nrf52840-pinctrl.dtsi:119 */
			group1 {
				psels = < 0x400001f >,
				        < 0x500001e >,
				        < 0x6000028 >; /* in zephyr/boards/nordic/nrf52840dk/nrf52840dk_nrf52840-pinctrl.dtsi:120 */
				low-power-enable;      /* in zephyr/boards/nordic/nrf52840dk/nrf52840dk_nrf52840-pinctrl.dtsi:123 */
			};
		};

		/* node '/pin-controller/spi2_default' defined in zephyr/boards/nordic/nrf52840dk/nrf52840dk_nrf52840-pinctrl.dtsi:127 */
		spi2_default: spi2_default {
			phandle = < 0xe >; /* in zephyr/boards/nordic/nrf52840dk/nrf52840dk_nrf52840.dts:245 */

			/* node '/pin-controller/spi2_default/group1' defined in zephyr/boards/nordic/nrf52840dk/nrf52840dk_nrf52840-pinctrl.dtsi:128 */
			group1 {
				psels = < 0x4000013 >,
				        < 0x5000014 >,
				        < 0x6000015 >; /* in zephyr/boards/nordic/nrf52840dk/nrf52840dk_nrf52840-pinctrl.dtsi:129 */
			};
		};

		/* node '/pin-controller/spi2_sleep' defined in zephyr/boards/nordic/nrf52840dk/nrf52840dk_nrf52840-pinctrl.dtsi:135 */
		spi2_sleep: spi2_sleep {
			phandle = < 0xf >; /* in zephyr/boards/nordic/nrf52840dk/nrf52840dk_nrf52840.dts:246 */

			/* node '/pin-controller/spi2_sleep/group1' defined in zephyr/boards/nordic/nrf52840dk/nrf52840dk_nrf52840-pinctrl.dtsi:136 */
			group1 {
				psels = < 0x4000013 >,
				        < 0x5000014 >,
				        < 0x6000015 >; /* in zephyr/boards/nordic/nrf52840dk/nrf52840dk_nrf52840-pinctrl.dtsi:137 */
				low-power-enable;      /* in zephyr/boards/nordic/nrf52840dk/nrf52840dk_nrf52840-pinctrl.dtsi:140 */
			};
		};

		/* node '/pin-controller/qspi_default' defined in zephyr/boards/nordic/nrf52840dk/nrf52840dk_nrf52840-pinctrl.dtsi:144 */
		qspi_default: qspi_default {
			phandle = < 0x12 >; /* in zephyr/boards/nordic/nrf52840dk/nrf52840dk_nrf52840.dts:252 */

			/* node '/pin-controller/qspi_default/group1' defined in zephyr/boards/nordic/nrf52840dk/nrf52840dk_nrf52840-pinctrl.dtsi:145 */
			group1 {
				psels = < 0x1d000013 >,
				        < 0x1f000014 >,
				        < 0x20000015 >,
				        < 0x21000016 >,
				        < 0x22000017 >,
				        < 0x1e000011 >;      /* in zephyr/boards/nordic/nrf52840dk/nrf52840dk_nrf52840-pinctrl.dtsi:146 */
				nordic,drive-mode = < 0x3 >; /* in zephyr/boards/nordic/nrf52840dk/nrf52840dk_nrf52840-pinctrl.dtsi:152 */
			};
		};

		/* node '/pin-controller/qspi_sleep' defined in zephyr/boards/nordic/nrf52840dk/nrf52840dk_nrf52840-pinctrl.dtsi:156 */
		qspi_sleep: qspi_sleep {
			phandle = < 0x13 >; /* in zephyr/boards/nordic/nrf52840dk/nrf52840dk_nrf52840.dts:253 */

			/* node '/pin-controller/qspi_sleep/group1' defined in zephyr/boards/nordic/nrf52840dk/nrf52840dk_nrf52840-pinctrl.dtsi:157 */
			group1 {
				psels = < 0x1d000013 >,
				        < 0x1f000014 >,
				        < 0x20000015 >,
				        < 0x21000016 >,
				        < 0x22000017 >; /* in zephyr/boards/nordic/nrf52840dk/nrf52840dk_nrf52840-pinctrl.dtsi:158 */
				low-power-enable;       /* in zephyr/boards/nordic/nrf52840dk/nrf52840dk_nrf52840-pinctrl.dtsi:163 */
			};

			/* node '/pin-controller/qspi_sleep/group2' defined in zephyr/boards/nordic/nrf52840dk/nrf52840dk_nrf52840-pinctrl.dtsi:166 */
			group2 {
				psels = < 0x1e000011 >; /* in zephyr/boards/nordic/nrf52840dk/nrf52840dk_nrf52840-pinctrl.dtsi:167 */
				low-power-enable;       /* in zephyr/boards/nordic/nrf52840dk/nrf52840dk_nrf52840-pinctrl.dtsi:168 */
				bias-pull-up;           /* in zephyr/boards/nordic/nrf52840dk/nrf52840dk_nrf52840-pinctrl.dtsi:169 */
			};
		};

		/* node '/pin-controller/spi3_default' defined in zephyr/boards/nordic/nrf52840dk/nrf52840dk_nrf52840-pinctrl.dtsi:173 */
		spi3_default: spi3_default {
			phandle = < 0x15 >; /* in app/boards/nrf52840dk_nrf52840.overlay:144 */

			/* node '/pin-controller/spi3_default/group1' defined in zephyr/boards/nordic/nrf52840dk/nrf52840dk_nrf52840-pinctrl.dtsi:174 */
			group1 {
				psels = < 0x500001c >,
				        < 0x600002a >,
				        < 0x400001d >; /* in app/boards/nrf52840dk_nrf52840.overlay:40 */
			};
		};

		/* node '/pin-controller/spi3_sleep' defined in zephyr/boards/nordic/nrf52840dk/nrf52840dk_nrf52840-pinctrl.dtsi:181 */
		spi3_sleep: spi3_sleep {
			phandle = < 0x16 >; /* in app/boards/nrf52840dk_nrf52840.overlay:145 */

			/* node '/pin-controller/spi3_sleep/group1' defined in zephyr/boards/nordic/nrf52840dk/nrf52840dk_nrf52840-pinctrl.dtsi:182 */
			group1 {
				psels = < 0x500001c >,
				        < 0x600002a >,
				        < 0x400001d >; /* in app/boards/nrf52840dk_nrf52840.overlay:48 */
				low-power-enable;      /* in app/boards/nrf52840dk_nrf52840.overlay:51 */
			};
		};
	};

	/* node '/entropy_bt_hci' defined in zephyr/dts/vendor/nordic/nrf_common.dtsi:33 */
	rng_hci: entropy_bt_hci {
		compatible = "zephyr,bt-hci-entropy"; /* in zephyr/dts/vendor/nordic/nrf_common.dtsi:34 */
		status = "okay";                      /* in zephyr/dts/vendor/nordic/nrf_common.dtsi:35 */
	};

	/* node '/sw-pwm' defined in zephyr/dts/vendor/nordic/nrf_common.dtsi:38 */
	sw_pwm: sw-pwm {
		compatible = "nordic,nrf-sw-pwm"; /* in zephyr/dts/vendor/nordic/nrf_common.dtsi:39 */
		status = "disabled";              /* in zephyr/dts/vendor/nordic/nrf_common.dtsi:40 */
		generator = < &timer1 >;          /* in zephyr/dts/vendor/nordic/nrf_common.dtsi:41 */
		clock-prescaler = < 0x0 >;        /* in zephyr/dts/vendor/nordic/nrf_common.dtsi:42 */
		#pwm-cells = < 0x3 >;             /* in zephyr/dts/vendor/nordic/nrf_common.dtsi:43 */
	};

	/* node '/cpus' defined in zephyr/dts/arm/nordic/nrf52840.dtsi:15 */
	cpus {
		#address-cells = < 0x1 >; /* in zephyr/dts/arm/nordic/nrf52840.dtsi:16 */
		#size-cells = < 0x0 >;    /* in zephyr/dts/arm/nordic/nrf52840.dtsi:17 */

		/* node '/cpus/cpu@0' defined in zephyr/dts/arm/nordic/nrf52840.dtsi:19 */
		cpu@0 {
			device_type = "cpu";           /* in zephyr/dts/arm/nordic/nrf52840.dtsi:20 */
			compatible = "arm,cortex-m4f"; /* in zephyr/dts/arm/nordic/nrf52840.dtsi:21 */
			reg = < 0x0 >;                 /* in zephyr/dts/arm/nordic/nrf52840.dtsi:22 */
			#address-cells = < 0x1 >;      /* in zephyr/dts/arm/nordic/nrf52840.dtsi:23 */
			#size-cells = < 0x1 >;         /* in zephyr/dts/arm/nordic/nrf52840.dtsi:24 */

			/* node '/cpus/cpu@0/itm@e0000000' defined in zephyr/dts/arm/nordic/nrf52840.dtsi:26 */
			itm: itm@e0000000 {
				compatible = "arm,armv7m-itm";     /* in zephyr/dts/arm/nordic/nrf52840.dtsi:27 */
				reg = < 0xe0000000 0x1000 >;       /* in zephyr/dts/arm/nordic/nrf52840.dtsi:28 */
				swo-ref-frequency = < 0x1e84800 >; /* in zephyr/dts/arm/nordic/nrf52840.dtsi:29 */
			};
		};
	};

	/* node '/clocks' defined in zephyr/dts/arm/nordic/nrf52840.dtsi:34 */
	clocks {

		/* node '/clocks/hfxo' defined in zephyr/dts/arm/nordic/nrf52840.dtsi:35 */
		hfxo: hfxo {
			compatible = "nordic,nrf52-hfxo"; /* in zephyr/dts/arm/nordic/nrf52840.dtsi:36 */
			clock-frequency = < 0x3d09000 >;  /* in zephyr/dts/arm/nordic/nrf52840.dtsi:37 */
			startup-time-us = < 0x578 >;      /* in zephyr/dts/arm/nordic/nrf52840.dtsi:38 */
			#clock-cells = < 0x0 >;           /* in zephyr/dts/arm/nordic/nrf52840.dtsi:39 */
		};
	};

	/* node '/leds' defined in zephyr/boards/nordic/nrf52840dk/nrf52840dk_nrf52840.dts:27 */
	leds {
		compatible = "gpio-leds"; /* in zephyr/boards/nordic/nrf52840dk/nrf52840dk_nrf52840.dts:28 */

		/* node '/leds/led_0' defined in zephyr/boards/nordic/nrf52840dk/nrf52840dk_nrf52840.dts:30 */
		led0: led_0 {
			gpios = < &gpio0 0xd 0x1 >; /* in zephyr/boards/nordic/nrf52840dk/nrf52840dk_nrf52840.dts:31 */
			label = "Green LED 0";      /* in zephyr/boards/nordic/nrf52840dk/nrf52840dk_nrf52840.dts:32 */
		};

		/* node '/leds/led_1' defined in zephyr/boards/nordic/nrf52840dk/nrf52840dk_nrf52840.dts:35 */
		led1: led_1 {
			gpios = < &gpio0 0xe 0x1 >; /* in zephyr/boards/nordic/nrf52840dk/nrf52840dk_nrf52840.dts:36 */
			label = "Green LED 1";      /* in zephyr/boards/nordic/nrf52840dk/nrf52840dk_nrf52840.dts:37 */
		};

		/* node '/leds/led_2' defined in zephyr/boards/nordic/nrf52840dk/nrf52840dk_nrf52840.dts:40 */
		led2: led_2 {
			gpios = < &gpio0 0xf 0x1 >; /* in zephyr/boards/nordic/nrf52840dk/nrf52840dk_nrf52840.dts:41 */
			label = "Green LED 2";      /* in zephyr/boards/nordic/nrf52840dk/nrf52840dk_nrf52840.dts:42 */
		};

		/* node '/leds/led_3' defined in zephyr/boards/nordic/nrf52840dk/nrf52840dk_nrf52840.dts:45 */
		led3: led_3 {
			gpios = < &gpio0 0x10 0x1 >; /* in zephyr/boards/nordic/nrf52840dk/nrf52840dk_nrf52840.dts:46 */
			label = "Green LED 3";       /* in zephyr/boards/nordic/nrf52840dk/nrf52840dk_nrf52840.dts:47 */
		};
	};

	/* node '/pwmleds' defined in zephyr/boards/nordic/nrf52840dk/nrf52840dk_nrf52840.dts:51 */
	pwmleds {
		compatible = "pwm-leds"; /* in zephyr/boards/nordic/nrf52840dk/nrf52840dk_nrf52840.dts:52 */

		/* node '/pwmleds/pwm_led_0' defined in zephyr/boards/nordic/nrf52840dk/nrf52840dk_nrf52840.dts:54 */
		pwm_led0: pwm_led_0 {
			pwms = < &pwm0 0x0 0x1312d00 0x1 >; /* in zephyr/boards/nordic/nrf52840dk/nrf52840dk_nrf52840.dts:55 */
		};
	};

	/* node '/buttons' defined in zephyr/boards/nordic/nrf52840dk/nrf52840dk_nrf52840.dts:59 */
	buttons {
		compatible = "gpio-keys"; /* in zephyr/boards/nordic/nrf52840dk/nrf52840dk_nrf52840.dts:60 */

		/* node '/buttons/button_0' defined in zephyr/boards/nordic/nrf52840dk/nrf52840dk_nrf52840.dts:62 */
		button0: button_0 {
			gpios = < &gpio1 0x9 0x11 >;    /* in app/boards/nrf52840dk_nrf52840.overlay:96 */
			label = "Push button switch 0"; /* in zephyr/boards/nordic/nrf52840dk/nrf52840dk_nrf52840.dts:64 */
			zephyr,code = < 0xb >;          /* in zephyr/boards/nordic/nrf52840dk/nrf52840dk_nrf52840.dts:65 */
		};

		/* node '/buttons/button_1' defined in zephyr/boards/nordic/nrf52840dk/nrf52840dk_nrf52840.dts:68 */
		button1: button_1 {
			gpios = < &gpio0 0xc 0x11 >;    /* in zephyr/boards/nordic/nrf52840dk/nrf52840dk_nrf52840.dts:69 */
			label = "Push button switch 1"; /* in zephyr/boards/nordic/nrf52840dk/nrf52840dk_nrf52840.dts:70 */
			zephyr,code = < 0x2 >;          /* in zephyr/boards/nordic/nrf52840dk/nrf52840dk_nrf52840.dts:71 */
		};

		/* node '/buttons/button_2' defined in zephyr/boards/nordic/nrf52840dk/nrf52840dk_nrf52840.dts:74 */
		button2: button_2 {
			gpios = < &gpio0 0x18 0x11 >;   /* in zephyr/boards/nordic/nrf52840dk/nrf52840dk_nrf52840.dts:75 */
			label = "Push button switch 2"; /* in zephyr/boards/nordic/nrf52840dk/nrf52840dk_nrf52840.dts:76 */
			zephyr,code = < 0x3 >;          /* in zephyr/boards/nordic/nrf52840dk/nrf52840dk_nrf52840.dts:77 */
		};

		/* node '/buttons/button_3' defined in zephyr/boards/nordic/nrf52840dk/nrf52840dk_nrf52840.dts:80 */
		button3: button_3 {
			gpios = < &gpio0 0x19 0x11 >;   /* in zephyr/boards/nordic/nrf52840dk/nrf52840dk_nrf52840.dts:81 */
			label = "Push button switch 3"; /* in zephyr/boards/nordic/nrf52840dk/nrf52840dk_nrf52840.dts:82 */
			zephyr,code = < 0x4 >;          /* in zephyr/boards/nordic/nrf52840dk/nrf52840dk_nrf52840.dts:83 */
		};
	};

	/* node '/connector' defined in zephyr/boards/nordic/nrf52840dk/nrf52840dk_nrf52840.dts:87 */
	arduino_header: connector {
		compatible = "arduino-header-r3";          /* in zephyr/boards/nordic/nrf52840dk/nrf52840dk_nrf52840.dts:88 */
		#gpio-cells = < 0x2 >;                     /* in zephyr/boards/nordic/nrf52840dk/nrf52840dk_nrf52840.dts:89 */
		gpio-map-mask = < 0xffffffff 0xffffffc0 >; /* in zephyr/boards/nordic/nrf52840dk/nrf52840dk_nrf52840.dts:90 */
		gpio-map-pass-thru = < 0x0 0x3f >;         /* in zephyr/boards/nordic/nrf52840dk/nrf52840dk_nrf52840.dts:91 */
		gpio-map = < 0x0 0x0 &gpio0 0x3 0x0 >,
		           < 0x1 0x0 &gpio0 0x4 0x0 >,
		           < 0x2 0x0 &gpio0 0x1c 0x0 >,
		           < 0x3 0x0 &gpio0 0x1d 0x0 >,
		           < 0x4 0x0 &gpio0 0x1e 0x0 >,
		           < 0x5 0x0 &gpio0 0x1f 0x0 >,
		           < 0x6 0x0 &gpio1 0x1 0x0 >,
		           < 0x7 0x0 &gpio1 0x2 0x0 >,
		           < 0x8 0x0 &gpio1 0x3 0x0 >,
		           < 0x9 0x0 &gpio1 0x4 0x0 >,
		           < 0xa 0x0 &gpio1 0x5 0x0 >,
		           < 0xb 0x0 &gpio1 0x6 0x0 >,
		           < 0xc 0x0 &gpio1 0x7 0x0 >,
		           < 0xd 0x0 &gpio1 0x8 0x0 >,
		           < 0xe 0x0 &gpio1 0xa 0x0 >,
		           < 0xf 0x0 &gpio1 0xb 0x0 >,
		           < 0x10 0x0 &gpio1 0xc 0x0 >,
		           < 0x11 0x0 &gpio1 0xd 0x0 >,
		           < 0x12 0x0 &gpio1 0xe 0x0 >,
		           < 0x13 0x0 &gpio1 0xf 0x0 >,
		           < 0x14 0x0 &gpio0 0x1a 0x0 >,
		           < 0x15 0x0 &gpio0 0x1b 0x0 >;   /* in zephyr/boards/nordic/nrf52840dk/nrf52840dk_nrf52840.dts:92 */
	};

	/* node '/analog-connector' defined in zephyr/boards/nordic/nrf52840dk/nrf52840dk_nrf52840.dts:116 */
	arduino_adc: analog-connector {
		compatible = "arduino,uno-adc";    /* in zephyr/boards/nordic/nrf52840dk/nrf52840dk_nrf52840.dts:117 */
		#io-channel-cells = < 0x1 >;       /* in zephyr/boards/nordic/nrf52840dk/nrf52840dk_nrf52840.dts:118 */
		io-channel-map = < 0x0 &adc 0x1 >,
		                 < 0x1 &adc 0x2 >,
		                 < 0x2 &adc 0x4 >,
		                 < 0x3 &adc 0x5 >,
		                 < 0x4 &adc 0x6 >,
		                 < 0x5 &adc 0x7 >; /* in zephyr/boards/nordic/nrf52840dk/nrf52840dk_nrf52840.dts:119 */
	};

	/* node '/sram0@2003f000' defined in app/socs/nrf52840.overlay:2 */
	sram0@2003f000 {
		compatible = "zephyr,memory-region",
		             "mmio-sram";              /* in app/socs/nrf52840.overlay:3 */
		reg = < 0x2003f000 0x1000 >;           /* in app/socs/nrf52840.overlay:4 */
		zephyr,memory-region = "RETAINED_MEM"; /* in app/socs/nrf52840.overlay:5 */
		status = "okay";                       /* in app/socs/nrf52840.overlay:6 */

		/* node '/sram0@2003f000/retainedmem' defined in app/socs/nrf52840.overlay:8 */
		retainedmem0: retainedmem {
			compatible = "zephyr,retained-ram"; /* in app/socs/nrf52840.overlay:9 */
			status = "okay";                    /* in app/socs/nrf52840.overlay:10 */
		};
	};

	/* node '/sram0@20007f7c' defined in app/socs/nrf52840.overlay:14 */
	sram0@20007f7c {
		compatible = "zephyr,memory-region",
		             "mmio-sram";                   /* in app/socs/nrf52840.overlay:15 */
		reg = < 0x20007f7c 0x4 >;                   /* in app/socs/nrf52840.overlay:16 */
		zephyr,memory-region = "DFU_DBL_RESET_MEM"; /* in app/socs/nrf52840.overlay:17 */
		status = "okay";                            /* in app/socs/nrf52840.overlay:18 */

		/* node '/sram0@20007f7c/retainedmem' defined in app/socs/nrf52840.overlay:20 */
		retainedmem {
			compatible = "zephyr,retained-ram"; /* in app/socs/nrf52840.overlay:21 */
			status = "okay";                    /* in app/socs/nrf52840.overlay:22 */
		};
	};

	/* node '/battery-divider' defined in app/boards/nrf52840dk_nrf52840.overlay:80 */
	battery-divider {
		compatible = "voltage-divider";   /* in app/boards/nrf52840dk_nrf52840.overlay:81 */
		status = "okay";                  /* in app/boards/nrf52840dk_nrf52840.overlay:82 */
		io-channels = < &adc 0x1 >;       /* in app/boards/nrf52840dk_nrf52840.overlay:83 */
		output-ohms = < 0xc738 >;         /* in app/boards/nrf52840dk_nrf52840.overlay:84 */
		full-ohms = < 0x24dd8 >;          /* in app/boards/nrf52840dk_nrf52840.overlay:85 */
		power-gpios = < &gpio1 0xd 0x0 >; /* in app/boards/nrf52840dk_nrf52840.overlay:86 */
	};

	/* node '/zephyr,user' defined in app/boards/nrf52840dk_nrf52840.overlay:89 */
	zephyr,user {
		int0-gpios = < &gpio1 0xb 0x0 >; /* in app/boards/nrf52840dk_nrf52840.overlay:90 */
		led-gpios = < &gpio0 0x1e 0x7 >; /* in app/boards/nrf52840dk_nrf52840.overlay:91 */
	};
};
